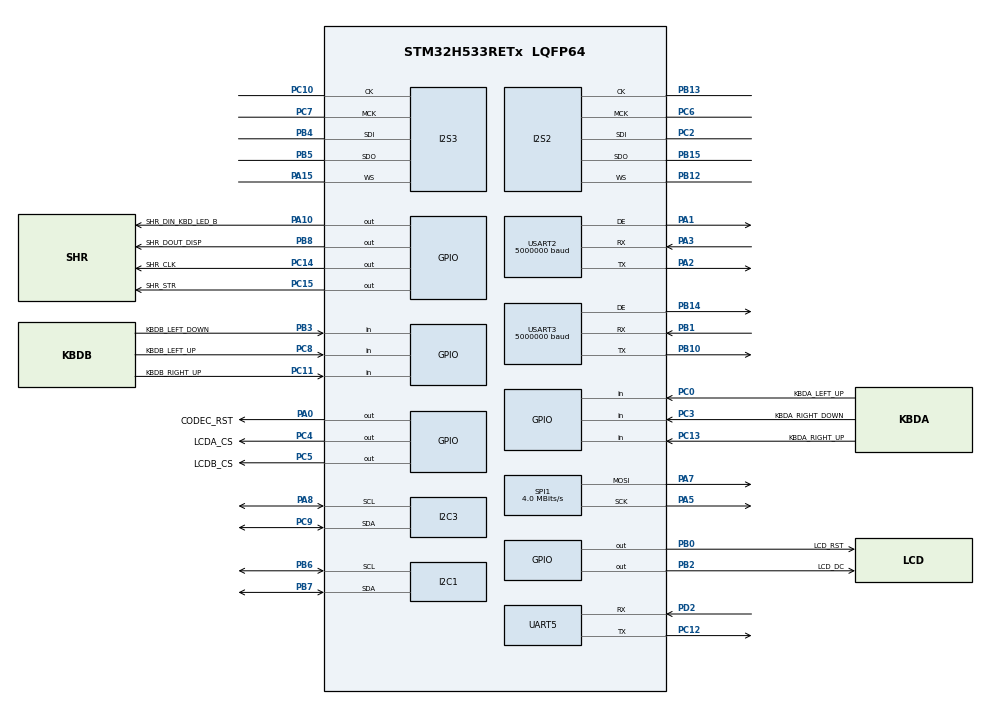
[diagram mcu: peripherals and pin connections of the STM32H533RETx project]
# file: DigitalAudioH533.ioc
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BOOTPATH.BootPathName=LEGACY
BOOTPATH.UserSelectedBootPath=LEGACY
CORTEX_M33_NS.userName=CORTEX_M33
GPDMA1.CIRCULARMODE_GPDMACH1=ENABLE
GPDMA1.CIRCULARMODE_GPDMACH3=ENABLE
GPDMA1.DESTINC_GPDMACH1=DMA_DINC_INCREMENTED
GPDMA1.DESTINC_GPDMACH3=DMA_DINC_INCREMENTED
GPDMA1.DIRECTION_GPDMACH0=DMA_MEMORY_TO_PERIPH
GPDMA1.DIRECTION_GPDMACH2=DMA_MEMORY_TO_PERIPH
GPDMA1.IPHANDLE_GPDMACH0-SIMPLEREQUEST_GPDMACH0=__NULL
GPDMA1.IPHANDLE_GPDMACH1-SIMPLEREQUEST_GPDMACH1=__NULL
GPDMA1.IPHANDLE_GPDMACH2-SIMPLEREQUEST_GPDMACH2=__NULL
GPDMA1.IPHANDLE_GPDMACH3-SIMPLEREQUEST_GPDMACH3=__NULL
GPDMA1.LINKALLOCATEDPORT_CIRCULAR_GPDMACH1=DMA_LINK_ALLOCATED_PORT1
GPDMA1.LINKALLOCATEDPORT_CIRCULAR_GPDMACH3=DMA_LINK_ALLOCATED_PORT1
GPDMA1.REQUEST_GPDMACH0=GPDMA1_REQUEST_USART3_TX
GPDMA1.REQUEST_GPDMACH1=GPDMA1_REQUEST_USART3_RX
GPDMA1.REQUEST_GPDMACH2=GPDMA1_REQUEST_USART2_TX
GPDMA1.REQUEST_GPDMACH3=GPDMA1_REQUEST_USART2_RX
GPDMA1.SRCINC_GPDMACH0=DMA_SINC_INCREMENTED
GPDMA1.SRCINC_GPDMACH2=DMA_SINC_INCREMENTED
GPDMA1.TRANSFERALLOCATEDPORTDEST_GPDMACH1=DMA_DEST_ALLOCATED_PORT1
GPDMA1.TRANSFERALLOCATEDPORTDEST_GPDMACH3=DMA_DEST_ALLOCATED_PORT1
GPDMA1.TRANSFERALLOCATEDPORTSRC_GPDMACH0=DMA_SRC_ALLOCATED_PORT1
GPDMA1.TRANSFERALLOCATEDPORTSRC_GPDMACH1=DMA_SRC_ALLOCATED_PORT0
GPDMA1.TRANSFERALLOCATEDPORTSRC_GPDMACH2=DMA_SRC_ALLOCATED_PORT1
GPDMA1.TRANSFEREVENTMODE_LL_CIRCULAR_GPDMACH1=DMA_TCEM_BLOCK_TRANSFER
GPDMA2.CIRCULARMODE_GPDMACH0=ENABLE
GPDMA2.CIRCULARMODE_GPDMACH1=ENABLE
GPDMA2.CIRCULARMODE_GPDMACH2=ENABLE
GPDMA2.CIRCULARMODE_GPDMACH3=ENABLE
GPDMA2.DESTDATAWIDTH_GPDMACH0=DMA_DEST_DATAWIDTH_WORD
GPDMA2.DESTDATAWIDTH_GPDMACH1=DMA_DEST_DATAWIDTH_WORD
GPDMA2.DESTDATAWIDTH_GPDMACH2=DMA_DEST_DATAWIDTH_WORD
GPDMA2.DESTDATAWIDTH_GPDMACH3=DMA_DEST_DATAWIDTH_WORD
GPDMA2.DESTINC_GPDMACH1=DMA_DINC_INCREMENTED
GPDMA2.DESTINC_GPDMACH3=DMA_DINC_INCREMENTED
GPDMA2.DIRECTION_GPDMACH0=DMA_MEMORY_TO_PERIPH
GPDMA2.DIRECTION_GPDMACH2=DMA_MEMORY_TO_PERIPH
GPDMA2.IPHANDLE_GPDMACH0-SIMPLEREQUEST_GPDMACH0=__NULL
GPDMA2.IPHANDLE_GPDMACH1-SIMPLEREQUEST_GPDMACH1=__NULL
GPDMA2.IPHANDLE_GPDMACH2-SIMPLEREQUEST_GPDMACH2=__NULL
GPDMA2.IPHANDLE_GPDMACH3-SIMPLEREQUEST_GPDMACH3=__NULL
GPDMA2.LINKALLOCATEDPORT_CIRCULAR_GPDMACH0=DMA_LINK_ALLOCATED_PORT1
GPDMA2.LINKALLOCATEDPORT_CIRCULAR_GPDMACH1=DMA_LINK_ALLOCATED_PORT1
GPDMA2.LINKALLOCATEDPORT_CIRCULAR_GPDMACH2=DMA_LINK_ALLOCATED_PORT1
GPDMA2.LINKALLOCATEDPORT_CIRCULAR_GPDMACH3=DMA_LINK_ALLOCATED_PORT1
GPDMA2.REQUEST_GPDMACH0=GPDMA2_REQUEST_SPI2_TX
GPDMA2.REQUEST_GPDMACH1=GPDMA2_REQUEST_SPI2_RX
GPDMA2.REQUEST_GPDMACH2=GPDMA2_REQUEST_SPI3_TX
GPDMA2.REQUEST_GPDMACH3=GPDMA2_REQUEST_SPI3_RX
GPDMA2.SRCDATAWIDTH_GPDMACH0=DMA_SRC_DATAWIDTH_WORD
GPDMA2.SRCDATAWIDTH_GPDMACH1=DMA_SRC_DATAWIDTH_WORD
GPDMA2.SRCDATAWIDTH_GPDMACH2=DMA_SRC_DATAWIDTH_WORD
GPDMA2.SRCDATAWIDTH_GPDMACH3=DMA_SRC_DATAWIDTH_WORD
GPDMA2.SRCINC_GPDMACH0=DMA_SINC_INCREMENTED
GPDMA2.SRCINC_GPDMACH2=DMA_SINC_INCREMENTED
GPDMA2.TRANSFERALLOCATEDPORTDEST_GPDMACH1=DMA_DEST_ALLOCATED_PORT1
GPDMA2.TRANSFERALLOCATEDPORTDEST_GPDMACH3=DMA_DEST_ALLOCATED_PORT1
GPDMA2.TRANSFERALLOCATEDPORTSRC_GPDMACH0=DMA_SRC_ALLOCATED_PORT1
GPDMA2.TRANSFERALLOCATEDPORTSRC_GPDMACH2=DMA_SRC_ALLOCATED_PORT1
I2C1.Timing=0x00707CBB
I2C3.Timing=0x00707CBB
I2S2.AudioFreq=AudioFreqCustomValue
I2S2.AudioFreqCustom=32000
I2S2.DataFormat=I2S_DATAFORMAT_32B
I2S2.ErrorAudioFreq=0.0 %
I2S2.Instance=SPI$Index
I2S2.RealAudioFreq=32.0 KHz
I2S3.AudioFreq=AudioFreqCustomValue
I2S3.AudioFreqCustom=32000
I2S3.DataFormat=I2S_DATAFORMAT_32B
I2S3.ErrorAudioFreq=0.0 %
I2S3.Instance=SPI$Index
I2S3.RealAudioFreq=32.0 KHz
Mcu.Family=STM32H5
Mcu.Name=STM32H533RETx
Mcu.Package=LQFP64
NVIC.PriorityGroup=NVIC_PRIORITYGROUP_4
NVIC.UART5_IRQn=true\:0\:0\:false\:false\:false\:true\:false\:true
PA0.GPIO_Label=CODEC_RST
PA0.GPIO_ModeDefaultOutputPP=GPIO_MODE_OUTPUT_OD
PA0.GPIO_PuPd=GPIO_PULLUP
PA0.PinState=GPIO_PIN_SET
PA0.Signal=GPIO_Output
PA1.GPIO_Speed=GPIO_SPEED_FREQ_HIGH
PA1.Mode=Hardware Flow Control (RS485)
PA1.Signal=USART2_DE
PA10.GPIO_Label=SHR_DIN_KBD_LED_B
PA10.PinState=GPIO_PIN_SET
PA10.Signal=GPIO_Output
PA13(JTMS/SWDIO).Mode=Serial_Wire
PA13(JTMS/SWDIO).Signal=DEBUG_JTMS-SWDIO
PA14(JTCK/SWCLK).Mode=Serial_Wire
PA14(JTCK/SWCLK).Signal=DEBUG_JTCK-SWCLK
PA15(JTDI).GPIO_Speed=GPIO_SPEED_FREQ_MEDIUM
PA15(JTDI).Mode=Full_Duplex_Master
PA15(JTDI).Signal=I2S3_WS
PA2.GPIO_Speed=GPIO_SPEED_FREQ_HIGH
PA2.Mode=Asynchronous
PA2.Signal=USART2_TX
PA3.GPIO_Speed=GPIO_SPEED_FREQ_HIGH
PA3.Mode=Asynchronous
PA3.PinAttribute=Free
PA3.Signal=USART2_RX
PA5.GPIO_Speed=GPIO_SPEED_FREQ_MEDIUM
PA5.Mode=TX_Only_Simplex_Unidirect_Master
PA5.Signal=SPI1_SCK
PA7.GPIO_Speed=GPIO_SPEED_FREQ_MEDIUM
PA7.Mode=TX_Only_Simplex_Unidirect_Master
PA7.Signal=SPI1_MOSI
PA8.Mode=I2C
PA8.Signal=I2C3_SCL
PB0.GPIO_Label=LCD_RST
PB0.Signal=GPIO_Output
PB1.GPIO_Speed=GPIO_SPEED_FREQ_HIGH
PB1.Mode=Asynchronous
PB1.PinAttribute=Free
PB1.Signal=USART3_RX
PB10.GPIO_Speed=GPIO_SPEED_FREQ_HIGH
PB10.Mode=Asynchronous
PB10.PinAttribute=Free
PB10.Signal=USART3_TX
PB12.GPIO_Speed=GPIO_SPEED_FREQ_MEDIUM
PB12.Mode=Full_Duplex_Master
PB12.PinAttribute=Free
PB12.Signal=I2S2_WS
PB13.GPIO_Speed=GPIO_SPEED_FREQ_MEDIUM
PB13.Mode=Full_Duplex_Master
PB13.PinAttribute=Free
PB13.Signal=I2S2_CK
PB14.GPIO_Speed=GPIO_SPEED_FREQ_HIGH
PB14.Mode=Hardware Flow Control (RS485)
PB14.PinAttribute=Free
PB14.Signal=USART3_DE
PB15.GPIO_Speed=GPIO_SPEED_FREQ_MEDIUM
PB15.Mode=Full_Duplex_Master
PB15.PinAttribute=Free
PB15.Signal=I2S2_SDO
PB2.GPIO_Label=LCD_DC
PB2.Signal=GPIO_Output
PB3(JTDO/TRACESWO).GPIO_Label=KBDB_LEFT_DOWN
PB3(JTDO/TRACESWO).GPIO_PuPd=GPIO_PULLUP
PB3(JTDO/TRACESWO).Signal=GPIO_Input
PB4(NJTRST).GPIO_Speed=GPIO_SPEED_FREQ_MEDIUM
PB4(NJTRST).Mode=Full_Duplex_Master
PB4(NJTRST).Signal=I2S3_SDI
PB5.GPIO_Speed=GPIO_SPEED_FREQ_MEDIUM
PB5.Mode=Full_Duplex_Master
PB5.Signal=I2S3_SDO
PB6.Mode=I2C
PB6.PinAttribute=Free
PB6.Signal=I2C1_SCL
PB7.Mode=I2C
PB7.PinAttribute=Free
PB7.Signal=I2C1_SDA
PB8.GPIO_Label=SHR_DOUT_DISP
PB8.PinAttribute=Free
PB8.Signal=GPIO_Output
PC0.GPIO_Label=KBDA_LEFT_UP
PC0.GPIO_PuPd=GPIO_PULLUP
PC0.Signal=GPIO_Input
PC10.GPIO_Speed=GPIO_SPEED_FREQ_MEDIUM
PC10.Mode=Full_Duplex_Master
PC10.Signal=I2S3_CK
PC11.GPIO_Label=KBDB_RIGHT_UP
PC11.GPIO_PuPd=GPIO_PULLUP
PC11.Signal=GPIO_Input
PC12.Mode=Asynchronous
PC12.PinAttribute=Free
PC12.Signal=UART5_TX
PC13.GPIO_Label=KBDA_RIGHT_UP
PC13.GPIO_PuPd=GPIO_PULLUP
PC13.Signal=GPIO_Input
PC14-OSC32_IN(OSC32_IN).GPIO_Label=SHR_CLK
PC14-OSC32_IN(OSC32_IN).PinAttribute=Free
PC14-OSC32_IN(OSC32_IN).Signal=GPIO_Output
PC15-OSC32_OUT(OSC32_OUT).GPIO_Label=SHR_STR
PC15-OSC32_OUT(OSC32_OUT).PinAttribute=Free
PC15-OSC32_OUT(OSC32_OUT).Signal=GPIO_Output
PC2.GPIO_Speed=GPIO_SPEED_FREQ_MEDIUM
PC2.Mode=Full_Duplex_Master
PC2.Signal=I2S2_SDI
PC3.GPIO_Label=KBDA_RIGHT_DOWN
PC3.GPIO_PuPd=GPIO_PULLUP
PC3.Signal=GPIO_Input
PC4.GPIO_Label=LCDA_CS
PC4.GPIO_Speed=GPIO_SPEED_FREQ_MEDIUM
PC4.Signal=GPIO_Output
PC5.GPIO_Label=LCDB_CS
PC5.GPIO_Speed=GPIO_SPEED_FREQ_MEDIUM
PC5.Signal=GPIO_Output
PC6.GPIO_Speed=GPIO_SPEED_FREQ_HIGH
PC6.Mode=Master_Clock_Activated
PC6.Signal=I2S2_MCK
PC7.GPIO_Speed=GPIO_SPEED_FREQ_HIGH
PC7.Mode=Master_Clock_Activated
PC7.Signal=I2S3_MCK
PC8.GPIO_Label=KBDB_LEFT_UP
PC8.GPIO_PuPd=GPIO_PULLUP
PC8.Signal=GPIO_Input
PC9.Mode=I2C
PC9.Signal=I2C3_SDA
PD2.Mode=Asynchronous
PD2.PinAttribute=Free
PD2.Signal=UART5_RX
PH0-OSC_IN(PH0).Mode=HSE-External-Oscillator
PH0-OSC_IN(PH0).Signal=RCC_OSC_IN
PH1-OSC_OUT(PH1).Mode=HSE-External-Oscillator
PH1-OSC_OUT(PH1).Signal=RCC_OSC_OUT
ProjectManager.HeapSize=0x200
ProjectManager.StackSize=0x400
ProjectManager.TargetToolchain=STM32CubeIDE
RCC.ADCFreq_Value=80000000
RCC.AHBFreq_Value=80000000
RCC.APB1Freq_Value=80000000
RCC.APB1TimFreq_Value=80000000
RCC.APB2Freq_Value=80000000
RCC.APB2TimFreq_Value=80000000
RCC.APB3Freq_Value=80000000
RCC.CKPERSourceSelection=RCC_CLKPSOURCE_HSE
RCC.CSI_VALUE=4000000
RCC.CortexFreq_Value=80000000
RCC.EPOD_VALUE=16000000
RCC.HCLKFreq_Value=80000000
RCC.HSE_VALUE=16000000
RCC.HSI48_VALUE=48000000
RCC.HSI_VALUE=64000000
RCC.I2C1CLockSelection=RCC_I2C1CLKSOURCE_PLL3R
RCC.I2C3CLockSelection=RCC_I2C3CLKSOURCE_PLL3R
RCC.LSE_VALUE=32768
RCC.LSIRC_VALUE=32000
RCC.PLL1P=4
RCC.PLL1Q=10
RCC.PLL2M=10
RCC.PLL2N=256
RCC.PLL2P=10
RCC.PLL2Q=10
RCC.PLL2Source=RCC_PLL2_SOURCE_HSE
RCC.PLL3N=8
RCC.PLL3Q=4
RCC.PLL3R=4
RCC.PLL3Source=RCC_PLL3_SOURCE_HSE
RCC.PLLN=20
RCC.PLLSourceVirtual=RCC_PLL1_SOURCE_HSE
RCC.SPI2CLockSelection=RCC_SPI2CLKSOURCE_PLL2P
RCC.SPI3CLockSelection=RCC_SPI3CLKSOURCE_PLL2P
RCC.SYSCLKFreq_VALUE=80000000
RCC.SYSCLKSource=RCC_SYSCLKSOURCE_PLLCLK
RCC.UART5CLockSelection=RCC_UART5CLKSOURCE_PLL3Q
RCC.USBFreq_Value=48000000
RCC.VCOOutputFreq_Value=320000000
SPI1.BaudRatePrescaler=SPI_BAUDRATEPRESCALER_8
SPI1.CLKPhase=SPI_PHASE_2EDGE
SPI1.CLKPolarity=SPI_POLARITY_HIGH
SPI1.CalculateBaudRate=4.0 MBits/s
SPI1.DataSize=SPI_DATASIZE_8BIT
SPI1.Direction=SPI_DIRECTION_2LINES_TXONLY
SPI1.Mode=SPI_MODE_MASTER
SPI1.VirtualType=VM_MASTER
TIM2.Prescaler=39999
TIM5.Prescaler=79
USART2.BaudRate=5000000
USART2.VirtualMode-Asynchronous=VM_ASYNC
USART2.VirtualMode-Hardware\ Flow\ Control\ (RS485)=VM_ASYNC
USART3.BaudRate=5000000
USART3.OverSampling=UART_OVERSAMPLING_16
USART3.VirtualMode-Asynchronous=VM_ASYNC
USART3.VirtualMode-Hardware\ Flow\ Control\ (RS485)=VM_ASYNC
VP_BOOTPATH_VS_BOOTPATH.Mode=BP_Activate
VP_CORTEX_M33_NS_VS_Hclk.Mode=Hclk_Mode
VP_GPDMA1_VS_GPDMACH0.Mode=SIMPLEREQUEST_GPDMACH0
VP_GPDMA1_VS_GPDMACH1.Mode=SIMPLEREQUEST_GPDMACH1
VP_GPDMA1_VS_GPDMACH2.Mode=SIMPLEREQUEST_GPDMACH2
VP_GPDMA1_VS_GPDMACH3.Mode=SIMPLEREQUEST_GPDMACH3
VP_GPDMA2_VS_GPDMACH0.Mode=SIMPLEREQUEST_GPDMACH0
VP_GPDMA2_VS_GPDMACH1.Mode=SIMPLEREQUEST_GPDMACH1
VP_GPDMA2_VS_GPDMACH2.Mode=SIMPLEREQUEST_GPDMACH2
VP_GPDMA2_VS_GPDMACH3.Mode=SIMPLEREQUEST_GPDMACH3
VP_ICACHE_VS_ICACHE.Mode=DefaultMode
VP_MEMORYMAP_VS_MEMORYMAP.Mode=CurAppReg
VP_PWR_VS_LPOM.Mode=PowerOptimisation
VP_PWR_VS_SECSignals.Mode=Security/Privilege
VP_TIM2_VS_ClockSourceINT.Mode=Internal
VP_TIM5_VS_ClockSourceINT.Mode=Internal
board=custom

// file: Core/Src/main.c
/* USER CODE BEGIN Header */
/**
********************************************************************************
* @file           : main.c
* @brief          : Main program body
********************************************************************************
*
* Copyright (c) 2026 Unicod
*
* Licensed under the Apache License, Version 2.0 (the "License");
* you may not use this file except in compliance with the License.
* You may obtain a copy of the License at
*
*     http://www.apache.org/licenses/LICENSE-2.0
*
* Unless required by applicable law or agreed to in writing, software
* distributed under the License is distributed on an "AS IS" BASIS,
* WITHOUT WARRANTIES OR CONDITIONS OF ANY KIND, either express or implied.
* See the License for the specific language governing permissions and
* limitations under the License.
*
********************************************************************************
*/
/* USER CODE END Header */
#include "main.h"

/* USER CODE BEGIN Includes */
#include <ctype.h>
#include <stdint.h>
#include <string.h>

#include "disp7seg.h"
#include "gitinfo.h"
#include "printf.h"
#include "sounds.h"
#include "tlv320aic3104_ctrl.h"
#include "u8g2.h"
#include "usart2_dma.h"
#include "usart3_dma.h"
#include "uart5_it.h"
#include "ui.h"
#include "wavetable.h"

/* USER CODE END Includes */

/* USER CODE BEGIN PTD */

#define AUDIO_TX_CHAN_CNT           2     // Audio channel count for sending on RS485 bus
#define AUDIO_BUF_SAMPLE_CNT        512   // Audio buffer size in samples (per channel)

typedef struct {
   const DMA_TypeDef* dma;       // GPDMA instance (GPDMA1 or GPDMA2)
   uint32_t    dmaChannel;       // DMA channel used for this audio DAC
   uint32_t*   dmaBuf;           // DMA buffer for audio samples (32-bit words, left justified 16-bit samples in upper half, stereo interleaved)
   uint32_t    dmaBufSizeBytes;  // Size of DMA buffer in bytes
   uint32_t    dmaBufSampleCnt;  // Number of audio samples (per channel) in DMA buffer (dmaBufSizeBytes / 4 / 2)
   uint32_t    PrevSampleIdx;    // Previous sample index processed in DMA buffer, used to detect new samples for processing
   uint8_t     AudioChSel;       // Audio channel selection by user for this DAC

   uint32_t    Phase;
   uint32_t    PhaseInc;         // phase increment
   int16_t     IncDir;           // phase increment direction for modulation: -1 or +1

   int16_t  AudioChanBuf[AUDIO_BUF_SAMPLE_CNT];   // Audio sample buffer for each channel, filled by audio ADC task and consumed by RS485 bus task. Each sample is 16-bit signed integer.
   uint16_t AudioWrPos;   // Write position in audio buffer (in samples)
   uint16_t AudioRdPos;   // Read position in audio buffer (in samples)
   uint16_t AudioDatCnt;  // Number of valid audio samples in buffer (per channel)
   uint8_t  playing;      // flag indicating if audio is currently playing (1) or buffering (0)
} AudioDac;

/* USER CODE END PTD */

/* USER CODE BEGIN PD */
#define ARRAY_COUNT(arr) (sizeof(arr) / sizeof((arr)[0]))

/* USER CODE END PD */

LL_DMA_LinkNodeTypeDef Node_GPDMA2_Channel1;
LL_DMA_LinkNodeTypeDef Node_GPDMA2_Channel0;
LL_DMA_LinkNodeTypeDef Node_GPDMA2_Channel3;
LL_DMA_LinkNodeTypeDef Node_GPDMA2_Channel2;

LL_DMA_LinkNodeTypeDef Node_GPDMA1_Channel3;
LL_DMA_LinkNodeTypeDef Node_GPDMA1_Channel1;

/* USER CODE BEGIN PV */

#define I2S2_RXDMA_BUF_SAMPLE_CNT   512
#define I2S2_TXDMA_BUF_SAMPLE_CNT   512

uint32_t I2S2RxDmaBuf[I2S2_RXDMA_BUF_SAMPLE_CNT][2] = {0};
uint32_t I2S2TxDmaBuf[I2S2_TXDMA_BUF_SAMPLE_CNT][2] = {0};

#define I2S3_RXDMA_BUF_SAMPLE_CNT   512
#define I2S3_TXDMA_BUF_SAMPLE_CNT   512

uint32_t I2S3RxDmaBuf[I2S3_RXDMA_BUF_SAMPLE_CNT][2] = {0};
uint32_t I2S3TxDmaBuf[I2S3_TXDMA_BUF_SAMPLE_CNT][2] = {0};

AudioDac AudioDac_A = {GPDMA2, LL_DMA_CHANNEL_0, (uint32_t*)I2S2TxDmaBuf, sizeof(I2S2TxDmaBuf), I2S2_TXDMA_BUF_SAMPLE_CNT, 0, 3, 0, (4UL << 14), 1};
AudioDac AudioDac_B = {GPDMA2, LL_DMA_CHANNEL_2, (uint32_t*)I2S3TxDmaBuf, sizeof(I2S3TxDmaBuf), I2S3_TXDMA_BUF_SAMPLE_CNT, 0, 4, 0, (4UL << 14), 1};

uint8_t Vol = 0;

// Display instances for OLED LCD A and LCD B
static u8g2_t LcdA;
static u8g2_t LcdB;

/* USER CODE END PV */

void SystemClock_Config(void);
void PeriphCommonClock_Config(void);
static void MX_GPIO_Init(void);
static void MX_GPDMA1_Init(void);
static void MX_GPDMA2_Init(void);
static void MX_ICACHE_Init(void);
static void MX_TIM5_Init(void);
static void MX_TIM2_Init(void);
static void MX_USART3_UART_Init(void);
static void MX_UART5_Init(void);
static void MX_USART2_UART_Init(void);
static void MX_I2S2_Init(void);
static void MX_I2C1_Init(void);
static void MX_I2S3_Init(void);
static void MX_I2C3_Init(void);
static void MX_SPI1_Init(void);

/* USER CODE BEGIN 0 */
static inline void LD2_On()     { LL_GPIO_SetOutputPin(  SHR_DIN_KBD_LED_B_GPIO_Port, SHR_DIN_KBD_LED_B_Pin); }
static inline void LD2_Off()    { LL_GPIO_ResetOutputPin(SHR_DIN_KBD_LED_B_GPIO_Port, SHR_DIN_KBD_LED_B_Pin); }
static inline void LD2_Toggle() { LL_GPIO_TogglePin(     SHR_DIN_KBD_LED_B_GPIO_Port, SHR_DIN_KBD_LED_B_Pin); }

static inline void LCDA_CS_Deselect()   { LL_GPIO_SetOutputPin( LCDA_CS_GPIO_Port, LCDA_CS_Pin);   }
static inline void LCDA_CS_Select()     { LL_GPIO_ResetOutputPin( LCDA_CS_GPIO_Port, LCDA_CS_Pin); }

static inline void LCDB_CS_Deselect()   { LL_GPIO_SetOutputPin( LCDB_CS_GPIO_Port, LCDB_CS_Pin);   }
static inline void LCDB_CS_Select()     { LL_GPIO_ResetOutputPin( LCDB_CS_GPIO_Port, LCDB_CS_Pin); }

static inline void LCD_DC_High()        { LL_GPIO_SetOutputPin( LCD_DC_GPIO_Port, LCD_DC_Pin);   }
static inline void LCD_DC_Low()         { LL_GPIO_ResetOutputPin( LCD_DC_GPIO_Port, LCD_DC_Pin); }

static inline void LCD_RST_High()       { LL_GPIO_SetOutputPin( LCD_RST_GPIO_Port, LCD_RST_Pin);   }
static inline void LCD_RST_Low()        { LL_GPIO_ResetOutputPin( LCD_RST_GPIO_Port, LCD_RST_Pin); }

/***************************************************************************//**
 * @brief Check if specified time interval has elapsed
 * @param tref Pointer to time reference variable [ms]
 * @param tcycle Time interval in milliseconds
 *//****************************************************************************/
static inline uint32_t TickChk(uint32_t *tref, int_fast16_t tcycle) {
   uint32_t t = LL_TIM_GetCounter(TIM2) / 2;    // 2kHz/2=1kHz
   int32_t tdif = t - *tref;
   if (tdif >= tcycle) {
      *tref += tcycle;
      return 1;
   }
   return 0;
}

/***************************************************************************//**
* @brief Character send interface for printf function
*//****************************************************************************/
void uart_putc (void* p, char c) {
   Uart5_PutByte(c);
}

/***************************************************************************//**
* @brief Audio statistics
*//****************************************************************************/
void AudioStat(int16_t left, int16_t right) {
   static int32_t SumL = 0;
   static int32_t SumR = 0;
   static int16_t MinL = 0;
   static int16_t MaxL = 0;
   static int16_t MinR = 0;
   static int16_t MaxR = 0;
   SumL += left;
   SumR += right;
   if (left < MinL) MinL = left;
   if (left > MaxL) MaxL = left;
   if (right < MinR) MinR = right;
   if (right > MaxR) MaxR = right;
   static uint32_t PrintDelay = 0;
   if (++PrintDelay == 32000) {   // print every 32000 samples (approx every 1s at 32kHz sample rate)
      PrintDelay = 0;
      printf("A:%d,%d L(%d %d) R(%d %d)\n", SumL/32000, SumR/32000, MinL, MaxL, MinR, MaxR);
      SumL = 0;
      SumR = 0;
      MinL = INT16_MAX;
      MaxL = INT16_MIN;
      MinR = INT16_MAX;
      MaxR = INT16_MIN;
   }
}

/***************************************************************************//**
* @brief Process received data from USART2 (DMA rx callback)
*//****************************************************************************/
void ProcessUsart2RxData(const uint8_t* data, uint16_t len) {
}

/***************************************************************************//**
* @brief Process received data from USART3 (DMA rx callback)
*
* Decode audio packets received on USART3 (RS485 bus) and store audio samples
* in buffer for playback.
*
* Packet format [bytes]:
* [Header1]
* [Header2]
* [Channel]
* [Sample1_L]
* [Sample1_H]
* [Sample2_L]
* [Sample2_H]
* ...
* [SampleN_L]
* [SampleN_H]
*
*//****************************************************************************/
void ProcessUsart3RxData(const uint8_t* data, uint16_t len) {
#if 0
   static uint32_t ByteCnt = 0;
   static uint32_t SampleCnt = 0;
   ByteCnt += len;
   const uint16_t PacketSize = 3 + 128 * 2;  // Packet header (3 bytes) + 128 samples * 2 bytes per sample
   if (ByteCnt >= PacketSize) {
      ByteCnt -= PacketSize;
      SampleCnt += 128;
      if (SampleCnt >= 32000) {
         SampleCnt -= 32000;
         printf("AudioRx %u ms\n", usTimerGetAbs() / 1000); // Print timestamp every 32k samples (every 1 second at 32kHz sample rate)
      }
   }
#endif

   #define  DAT_IDX_START1       (-3)
   #define  DAT_IDX_START2       (DAT_IDX_START1 + 1)
   #define  DAT_IDX_CHANNEL      (DAT_IDX_START2 + 1)
   #define  AUDIO_PACKET_SIZE    256
   #define  AUDIO_CHANNELS       8

   #define  CIN_START1     111
   #define  CIN_START2     222

   static int16_t DatCnt = DAT_IDX_START1;
   static uint8_t ChanMatchA = 0;
   static uint8_t ChanMatchB = 0;
   static uint8_t LSB = 0;

   uint8_t ovfdiag = 1;
   for (size_t i=0; i<len; i++) {
      uint8_t d = data[i];
      switch (DatCnt) {
         case DAT_IDX_START1: {
            if (d == CIN_START1) DatCnt++;
         }break;
         case DAT_IDX_START2: {
            if (d == CIN_START2) DatCnt++;
            else DatCnt = DAT_IDX_START1;       // reset
         }break;
         case DAT_IDX_CHANNEL: {
            if (d < AUDIO_CHANNELS) {           // channel number range OK
               ChanMatchA = (d == AudioDac_A.AudioChSel) ? 1 : 0; // check channel number
               ChanMatchB = (d == AudioDac_B.AudioChSel) ? 1 : 0;
               DatCnt++;
               //printf("Ch%u\n", AudioChan);
            }else {                             // channel number out of range (invalid packet)
               DatCnt = DAT_IDX_START1;         // reset
            }
         }break;
         default: {
            if ((DatCnt & 1) == 0) {   // even index: LSByte
               LSB = d;                // store LSByte
            }else {                    // odd index: MSByte
               int16_t sample = ((uint16_t)d << 8) | LSB;   // combine MSByte and LSByte to form signed 16-bit audio sample
               //AudioStat(sample, 0);

               // Store received audio samples from RS485 to audio buffer
               if (ChanMatchA) {
                  AudioDac* d = &AudioDac_A;
                  if (d->AudioDatCnt < AUDIO_BUF_SAMPLE_CNT-1) {
                     d->AudioDatCnt++;
                     d->AudioWrPos++; // increment position
                     if (d->AudioWrPos >= AUDIO_BUF_SAMPLE_CNT) d->AudioWrPos = 0;  // wrap around if end of buffer reached
                     d->AudioChanBuf[d->AudioWrPos] = sample;     // store audio sample
                  }else {
                     if (ovfdiag) {
                        ovfdiag = 0;
                        printf("f");   // overflow
                     }
                  }
               }
               if (ChanMatchB) {
                  AudioDac* d = &AudioDac_B;
                  if (d->AudioDatCnt < AUDIO_BUF_SAMPLE_CNT-1) {
                     d->AudioDatCnt++;
                     d->AudioWrPos++; // increment position
                     if (d->AudioWrPos >= AUDIO_BUF_SAMPLE_CNT) d->AudioWrPos = 0;  // wrap around if end of buffer reached
                     d->AudioChanBuf[d->AudioWrPos] = sample;     // store audio sample
                  }else {
                     if (ovfdiag) {
                        ovfdiag = 0;
                        printf("F");   // overflow
                     }
                  }
               }
            }
            if (++DatCnt == AUDIO_PACKET_SIZE) DatCnt = DAT_IDX_START1; // done
         }break;
      }
   }

}

/***************************************************************************//**
* @brief  List specified registers of TLV320AIC3204 codec for debugging
*//****************************************************************************/
void TLV320_AIC3204_DumpRegs(void) {
   printf("TLV320_AIC3204: Dumping registers...\n");

   CODEC_SELECT    codec = CODEC_A;
   TLV_PAGE_SELECT page = TLV_PAGE_0;
   uint8_t         reg_list[] = { 0,2,3,4,5,6,7,8,9,10,11,47,51,43,37,44,64,65,38 };

   for (size_t i = 0; i < ARRAY_COUNT(reg_list); i++) {
      uint8_t reg = reg_list[i];
      int16_t val = TlvReadReg(codec, page, reg);
      printf("Reg %2u: 0x%02X (%d) \n", reg, val, val);
   }

   printf("TLV320_AIC3204: Dump done\n");
}

/***************************************************************************//**
* @brief   TLV320AIC3204 codec init with basic config for stereo playing (DAC)
*//****************************************************************************/
void TLV320_AIC3204_Init() {
   for (uint8_t codec = CODEC_A; codec <= CODEC_B; codec++) {
      TlvWriteReg(codec, TLV_PAGE_0,   3, 0x10);
      TlvWriteReg(codec, TLV_PAGE_0,   7, 0x0A);
      TlvWriteReg(codec, TLV_PAGE_0,   9, 0x10);
      TlvWriteReg(codec, TLV_PAGE_0,  47, 0x80);
      TlvWriteReg(codec, TLV_PAGE_0,  51, 0x09);
      TlvWriteReg(codec, TLV_PAGE_0,  43, 0x00);
      TlvWriteReg(codec, TLV_PAGE_0,  37, 0xD0);
      TlvWriteReg(codec, TLV_PAGE_0,  44, 0x00);
      TlvWriteReg(codec, TLV_PAGE_0,  64, 0x80);
      TlvWriteReg(codec, TLV_PAGE_0,  65, 0x09);
      TlvWriteReg(codec, TLV_PAGE_0,  38, 0x0C);
      TlvWriteReg(codec, TLV_PAGE_0, 101, 0x01);
      TlvWriteReg(codec, TLV_PAGE_0, 102, 0x02);

      TlvWriteReg(codec, TLV_PAGE_0,  15, 0x40);
      TlvWriteReg(codec, TLV_PAGE_0,  16, 0x40);
      TlvWriteReg(codec, TLV_PAGE_0,  17, 0xFF);
      TlvWriteReg(codec, TLV_PAGE_0,  18, 0xF0);
      TlvWriteReg(codec, TLV_PAGE_0,  19, 0x0D);
      TlvWriteReg(codec, TLV_PAGE_0,  21, 0x80);
      TlvWriteReg(codec, TLV_PAGE_0,  22, 0xFD);
      TlvWriteReg(codec, TLV_PAGE_0,  24, 0xF8);
      TlvWriteReg(codec, TLV_PAGE_0,  25, 0x80);
      TlvWriteReg(codec, TLV_PAGE_0,  40, 0xC1);
      TlvWriteReg(codec, TLV_PAGE_0,  41, 0x02);
      TlvWriteReg(codec, TLV_PAGE_0,  42, 0x88);
      TlvWriteReg(codec, TLV_PAGE_0,  46, 0x00);
      TlvWriteReg(codec, TLV_PAGE_0,  49, 0x00);
      TlvWriteReg(codec, TLV_PAGE_0,  50, 0x00);
      TlvWriteReg(codec, TLV_PAGE_0,  53, 0x00);
      TlvWriteReg(codec, TLV_PAGE_0,  54, 0x00);
      TlvWriteReg(codec, TLV_PAGE_0,  56, 0x00);
      TlvWriteReg(codec, TLV_PAGE_0,  57, 0x00);
      TlvWriteReg(codec, TLV_PAGE_0,  58, 0x01);
      TlvWriteReg(codec, TLV_PAGE_0,  60, 0x00);
      TlvWriteReg(codec, TLV_PAGE_0,  61, 0x00);
      TlvWriteReg(codec, TLV_PAGE_0,  63, 0x00);
      TlvWriteReg(codec, TLV_PAGE_0,  67, 0x00);
      TlvWriteReg(codec, TLV_PAGE_0,  68, 0x00);
      TlvWriteReg(codec, TLV_PAGE_0,  70, 0x00);
      TlvWriteReg(codec, TLV_PAGE_0,  71, 0x00);
      TlvWriteReg(codec, TLV_PAGE_0,  72, 0x01);
   }
}

void Fill_I2S_Buffer(AudioDac* dac, uint32_t start_sample, uint32_t sample_count) {
   uint_fast8_t doubling = 0;
   uint_fast8_t dropping = 0;

   for (uint32_t i = 0; i < sample_count; i++) {
      int16_t pcmsample = 0;

      switch (dac->AudioChSel) {
         case 9: {
            uint32_t frac = dac->Phase & 0x3FFF;        // fractional part for interpolation (14 bits)
            uint16_t idx  = dac->Phase >> 14;           // integer part: array index
            uint16_t idx2 = (idx + 1) % ARRAY_COUNT(Wave_Sin); // next index for linear interpolation
            int32_t pcm1 = Wave_Sin[idx];          // sine waveform
            int32_t pcm2 = Wave_Sin[idx2];         // next sample for interpolation
            pcmsample = pcm1 + ((pcm2 - pcm1) * frac >> 14); // linear interpolation
            pcmsample = pcmsample / 2;             // reduce amplitude
            dac->Phase = (dac->Phase + dac->PhaseInc) % (ARRAY_COUNT(Wave_Sin) << 14); // phase accumulator with wrap-around
            if (dac->AudioChSel == 5) dac->PhaseInc += dac->IncDir;  // Chsel: 6=fixed freq, 5=sweep up and down
            if (dac->PhaseInc < ( 4UL << 14)) dac->IncDir =  1; // minimum frequency reached, change direction to up
            if (dac->PhaseInc > (16UL << 14)) dac->IncDir = -1; // maximum frequency reached, change direction to down
         }break;
         case 7: {
            uint32_t frac = dac->Phase & 0x3FFF;        // fractional part for interpolation (14 bits)
            uint16_t idx  = dac->Phase >> 14;           // integer part: array index
            uint16_t idx2 = (idx + 1) % ARRAY_COUNT(Wave_Organ); // next index for linear interpolation
            int32_t pcm1 = Wave_Organ[idx];          // sine waveform
            int32_t pcm2 = Wave_Organ[idx2];         // next sample for interpolation
            pcmsample = pcm1 + ((pcm2 - pcm1) * frac >> 14); // linear interpolation
            pcmsample = pcmsample / 2;             // reduce amplitude
            dac->Phase = (dac->Phase + dac->PhaseInc) % (ARRAY_COUNT(Wave_Organ) << 14); // phase accumulator with wrap-around
            if (dac->AudioChSel == 7) dac->PhaseInc += dac->IncDir;  // Chsel: 3=fixed freq, 4=sweep up and down
            if (dac->PhaseInc < ( 4UL << 14)) dac->IncDir =  1; // minimum frequency reached, change direction to up
            if (dac->PhaseInc > (16UL << 14)) dac->IncDir = -1; // maximum frequency reached, change direction to down
         }break;

         case 6:
         case 5:
         case 4:
         case 3:
         case 2:
         case 1:
         case 0: {
            if (dac->AudioDatCnt < (AUDIO_BUF_SAMPLE_CNT * 1 / 8)) {    // too few samples in input buffer
               if (doubling == 0) doubling = 10;
            }
            if (dac->playing) {
               if (dac->AudioDatCnt == 0) {    // no samples to play
                  pcmsample = 0;          // mute output
                  dac->playing = 0;       // stop playing until buffer is refilled
                  printf("x");
               } else {
                  int16_t d = dac->AudioChanBuf[dac->AudioRdPos];  // read audio sample
                  pcmsample = d;                         // normal playback
                  dac->AudioDatCnt--;
                  dac->AudioRdPos++;
                  if (dac->AudioRdPos >= AUDIO_BUF_SAMPLE_CNT) dac->AudioRdPos = 0;
               }
            } else {    // Buffering (wait..)
               pcmsample = 0;
               if (dac->AudioDatCnt > (AUDIO_BUF_SAMPLE_CNT / 2)) {
                  dac->playing = 1;
                  printf("w");
               }
            }
            if (dac->AudioDatCnt > (AUDIO_BUF_SAMPLE_CNT * 7 / 8)) { // too many samples in input buffer
               if (dropping == 0) dropping = 10;
            }
         }break;
      }
      int32_t frame = pcmsample << 16; // convert to 32-bit sample with 16-bit left justified
      uint32_t pos = (start_sample + i) * 2;  // Stereo: L,R
      dac->dmaBuf[pos + 0] = frame/4;   // Left
      dac->dmaBuf[pos + 1] = frame/4;   // Right

      if (doubling == 10) {
         if (i<sample_count-1) {
            int32_t frame = pcmsample << 16; // convert to 32-bit sample with 16-bit left justified
            uint32_t pos = (start_sample + i) * 2;  // Stereo: L,R
            dac->dmaBuf[pos + 0] = frame/4;   // Left (duplicate sample)
            dac->dmaBuf[pos + 1] = frame/4;   // Right
            i++;
            if (dac->playing) printf("+");
         }
      }
      if (doubling) doubling--;

      if (dropping == 5) {
         dac->AudioDatCnt--;
         dac->AudioRdPos++;  // drop sample (no output for this sample)
         if (dac->AudioRdPos >= AUDIO_BUF_SAMPLE_CNT) dac->AudioRdPos = 0;
         if (dac->playing) printf("-");
      }
      if (dropping) dropping--;

   }
}

void AudioDAC_Task(AudioDac* dac) {
   uint32_t dma_ptr = dac->dmaBufSizeBytes - LL_DMA_GetBlkDataLength(dac->dma, dac->dmaChannel);
   uint32_t sample_idx = dma_ptr / 8; // Word = 4 bytes * 2 channels = 8 bytes per sample

   if (sample_idx != dac->PrevSampleIdx) {
      uint32_t free_samples;
      if (sample_idx > dac->PrevSampleIdx) {
         free_samples = sample_idx - dac->PrevSampleIdx;         // normal case: DMA is in between old and new index
         Fill_I2S_Buffer(dac, dac->PrevSampleIdx, free_samples);
      } else {
         free_samples = dac->dmaBufSampleCnt - dac->PrevSampleIdx;   // Wrap-around
         Fill_I2S_Buffer(dac, dac->PrevSampleIdx, free_samples);     // first the rest until end of buffer
         if (sample_idx > 0) {
            Fill_I2S_Buffer(dac, 0, sample_idx);
         }
      }

      dac->PrevSampleIdx = sample_idx;
   }
   //printf("dma_ptr:%u dma_word_index:%u sample_index:%u\n", dma_ptr, dma_word_index, sample_index);
}

void Proc_I2S_Buffer(uint32_t *buf, uint32_t start_sample, uint32_t sample_count) {
   enum { BUFCNT = 7 };
   static uint8_t Buf[BUFCNT][512];
   // Create audio packets from received I2S samples and send on USART2 (RS485 bus)
   for (uint32_t i = 0; i < sample_count; i++) {
      uint32_t pos = (start_sample + i) * 2;  // Stereo: L,R
      int16_t left  = buf[pos + 0] >> 16;   // convert back to 16-bit sample from 32-bit left justified
      int16_t right = buf[pos + 1] >> 16;   // convert back to 16-bit sample from 32-bit left justified
      {
         static uint16_t ByteTxIdx = 0;   // byte index for filling audio packet buffer
         static uint16_t SampleTxIdx = 0; // index for counting audio samples in current packet
         static uint32_t PcmPos = 0;      // position in PCM sample stream [samples]
         static uint32_t Phase = 0;       // phase accumulator for sine wave generation
         static const uint32_t PhaseInc = (4UL << 14) + 2345;  // phase increment for sine wave generation (controls frequency)
         if (SampleTxIdx == 0) {          // start of new packet, fill header
            ByteTxIdx = 0;
            for (int b=0; b<BUFCNT; b++) Buf[b][ByteTxIdx] = CIN_START1; // Packet header byte 1
            ByteTxIdx++;
            for (int b=0; b<BUFCNT; b++) Buf[b][ByteTxIdx] = CIN_START2; // Packet header byte 2
            ByteTxIdx++;
            for (int b=0; b<BUFCNT; b++) Buf[b][ByteTxIdx] = b;          // channel number
            ByteTxIdx++;
         }
         enum { AUDIO_PACKET_HDR_SIZE   = 3   };   // header size in bytes
         enum { AUDIO_PACKET_SAMPLE_CNT = 128 };   // number of audio samples in one packet
         if (SampleTxIdx < AUDIO_PACKET_SAMPLE_CNT) {
            PcmPos++;   // increment position in PCM sample stream
            if (PcmPos > (PCM_DolmetscheranlageLen + 2*32000)
            &&  PcmPos > (PCM_InterpreterSystemLen + 2*32000)
            &&  PcmPos > (PCM_TolmacsrendszerLen   + 2*32000)
            ) {
               PcmPos = 0;
            }
            int16_t s_de = PCM_Dolmetscheranlage[PcmPos];
            int16_t s_en = PCM_InterpreterSystem[PcmPos];
            int16_t s_hu = PCM_Tolmacsrendszer[PcmPos];
            if (PcmPos >= PCM_DolmetscheranlageLen) s_de = 0;
            if (PcmPos >= PCM_InterpreterSystemLen) s_en = 0;
            if (PcmPos >= PCM_TolmacsrendszerLen)   s_hu = 0;

            uint32_t frac = Phase & 0x3FFF;        // fractional part for interpolation (14 bits)
            uint16_t idx  = Phase >> 14;           // integer part: array index
            uint16_t idx2 = (idx + 1) % ARRAY_COUNT(Wave_Sin); // next index for linear interpolation
            int32_t pcm1 = Wave_Sin[idx];          // sine waveform
            int32_t pcm2 = Wave_Sin[idx2];         // next sample for interpolation
            int16_t s_sin = pcm1 + ((pcm2 - pcm1) * frac >> 14); // linear interpolation
            s_sin = s_sin / 2;             // reduce amplitude
            Phase = (Phase + PhaseInc) % (ARRAY_COUNT(Wave_Sin) << 14); // phase accumulator with wrap-around

            // Low byte of 16 bit audio sample
            Buf[0][ByteTxIdx] = left & 0xFF;   // store low byte of audio sample in packet buffer
            Buf[1][ByteTxIdx] = right & 0xFF;
            Buf[2][ByteTxIdx] = s_de & 0xFF;
            Buf[3][ByteTxIdx] = s_en & 0xFF;
            Buf[4][ByteTxIdx] = s_hu & 0xFF;
            Buf[5][ByteTxIdx] = 0;
            Buf[6][ByteTxIdx] = s_sin & 0xFF;
            ByteTxIdx++;

            // High byte of 16 bit audio sample
            Buf[0][ByteTxIdx] = left >> 8;     // store high byte of audio sample in packet buffer
            Buf[1][ByteTxIdx] = right >> 8;
            Buf[2][ByteTxIdx] = s_de >> 8;
            Buf[3][ByteTxIdx] = s_en >> 8;
            Buf[4][ByteTxIdx] = s_hu >> 8;
            Buf[5][ByteTxIdx] = 0;
            Buf[6][ByteTxIdx] = s_sin >> 8;
            ByteTxIdx++;
            SampleTxIdx++;
         }
         if (SampleTxIdx == AUDIO_PACKET_SAMPLE_CNT) {         // packet is full, send it
            Usart2_TxBufWrite(Buf[0], ByteTxIdx, 0);   // write packet to USART2 DMA buffer
            Usart2_TxBufWrite(Buf[1], ByteTxIdx, 0);   // write packet to USART2 DMA buffer
            Usart2_TxBufWrite(Buf[2], ByteTxIdx, 0);   // write packet to USART2 DMA buffer
            Usart2_TxBufWrite(Buf[3], ByteTxIdx, 0);   // write packet to USART2 DMA buffer
            Usart2_TxBufWrite(Buf[4], ByteTxIdx, 0);   // write packet to USART2 DMA buffer
            Usart2_TxBufWrite(Buf[5], ByteTxIdx, 0);   // write packet to USART2 DMA buffer
            Usart2_TxBufWrite(Buf[6], ByteTxIdx, 1);   // write packet to USART2 DMA buffer and flush (start transfer)
            ByteTxIdx = 0;    // reset byte index for next packet
            SampleTxIdx = 0;  // reset sample index for next packet
         }
      }
      AudioStat(left, right);
   }
}

void AudioADC_Task(void) {
   static uint32_t old_sample_index = 0;
   // DMA pointer --> Word-Index
   uint32_t dma_ptr = sizeof(I2S2RxDmaBuf) - LL_DMA_GetBlkDataLength(GPDMA2, LL_DMA_CHANNEL_1);
   uint32_t sample_index = dma_ptr / 8; // Word = 4 bytes * 2 channels = 8 bytes per sample

   if (sample_index != old_sample_index) {
      uint32_t free_samples;
      if (sample_index > old_sample_index) {
         free_samples = sample_index - old_sample_index;         // normal case: DMA is in between old and new index
         Proc_I2S_Buffer(I2S2RxDmaBuf[0], old_sample_index, free_samples);
      } else {
         free_samples = I2S2_RXDMA_BUF_SAMPLE_CNT - old_sample_index;         // Wrap-around
         Proc_I2S_Buffer(I2S2RxDmaBuf[0], old_sample_index, free_samples); // first the rest until end of buffer
         if (sample_index > 0) {
            Proc_I2S_Buffer(I2S2RxDmaBuf[0], 0, sample_index);
         }
      }

      old_sample_index = sample_index;
   }
   //printf("dma_ptr:%u dma_word_index:%u sample_index:%u\n", dma_ptr, dma_word_index, sample_index);
}

/***************************************************************************//**
* @brief  Handle keyboard input and update state
*//****************************************************************************/
static inline void Kbd_Task(void) {
   static uint32_t KbdPrev = 0;
   uint32_t k = Kbd_ReadState();
   uint32_t pressed =   k & ~KbdPrev;  // newly pressed keys
   uint32_t released = ~k &  KbdPrev;  // newly released keys
   for (uint16_t i=0; pressed | released; i++) {
      if (pressed & 1) {
         UI_EventProcKbd(i);                    // key pressed
      }
      if (released & 1) {
         UI_EventProcKbd(i + 256);              // key released
      }
      pressed >>= 1;
      released >>= 1;
   }
   KbdPrev = k;
}

void AudioSetChannelA(uint8_t chan) { AudioDac_A.AudioChSel = chan; }
void AudioSetChannelB(uint8_t chan) { AudioDac_B.AudioChSel = chan; }

/***************************************************************************//**
* @brief  GPIO and delay callback for u8g2 library (LCD-A control)
*//****************************************************************************/
uint8_t u8x8_stm32_gpio_and_delay_LcdA(U8X8_UNUSED u8x8_t *u8x8, U8X8_UNUSED uint8_t msg, U8X8_UNUSED uint8_t arg_int, U8X8_UNUSED void *arg_ptr) {
   switch (msg) {
   case U8X8_MSG_GPIO_AND_DELAY_INIT:
      LL_mDelay(1);
      break;
   case U8X8_MSG_DELAY_MILLI:
      LL_mDelay(arg_int);
      break;
   case U8X8_MSG_GPIO_CS:
      if (arg_int) LCDA_CS_Deselect();
      else         LCDA_CS_Select();
      break;
   case U8X8_MSG_GPIO_DC:
      if (arg_int) LCD_DC_High();
      else         LCD_DC_Low();
      break;
   case U8X8_MSG_GPIO_RESET:
      if (arg_int) LCD_RST_High();
      else         LCD_RST_Low();
      break;
   }
   return 1;
}

/***************************************************************************//**
* @brief  GPIO and delay callback for u8g2 library (LCD-B control)
*//****************************************************************************/
uint8_t u8x8_stm32_gpio_and_delay_LcdB(U8X8_UNUSED u8x8_t *u8x8, U8X8_UNUSED uint8_t msg, U8X8_UNUSED uint8_t arg_int, U8X8_UNUSED void *arg_ptr) {
   switch (msg) {
   case U8X8_MSG_GPIO_AND_DELAY_INIT:
      LL_mDelay(1);
      break;
   case U8X8_MSG_DELAY_MILLI:
      LL_mDelay(arg_int);
      break;
   case U8X8_MSG_GPIO_CS:
      if (arg_int) LCDB_CS_Deselect();
      else         LCDB_CS_Select();
      break;
   case U8X8_MSG_GPIO_DC:
      if (arg_int) LCD_DC_High();
      else         LCD_DC_Low();
      break;
   case U8X8_MSG_GPIO_RESET:
      // Shared reset pin for both LCDs, handled in LcdA callback
      // Initialization order: first LcdA, then LcdB!
      // Resetting in LcdA callback will reset both LCDs
      break;
   }
   return 1;
}

/***************************************************************************//**
* @brief  Byte-level communication callback for u8g2 library (4-wire hardware SPI)
*//****************************************************************************/
uint8_t u8x8_byte_4wire_hw_spi(u8x8_t *u8x8, uint8_t msg, uint8_t arg_int, void *arg_ptr) {
   switch (msg) {
   case U8X8_MSG_BYTE_SEND:
      uint8_t* dat = (uint8_t*)arg_ptr;
      for (uint16_t i = 0; i < arg_int; i++) {
         while (!LL_SPI_IsActiveFlag_TXP(SPI1)); // wait until transmit FIFO has space
         LL_SPI_TransmitData8(SPI1, dat[i]);
      }
      while (!LL_SPI_IsActiveFlag_TXC(SPI1)); // Ensure the last byte has been physically transmitted (wait for TXC)
      break;
   case U8X8_MSG_BYTE_INIT:
      u8x8_gpio_SetCS(u8x8, u8x8->display_info->chip_disable_level);
      break;
   case U8X8_MSG_BYTE_SET_DC:
      u8x8_gpio_SetDC(u8x8, arg_int);
      break;
   case U8X8_MSG_BYTE_START_TRANSFER:
      LL_SPI_Enable(SPI1);
      LL_SPI_StartMasterTransfer(SPI1);
      u8x8_gpio_SetCS(u8x8, u8x8->display_info->chip_enable_level);
      break;
   case U8X8_MSG_BYTE_END_TRANSFER:
      u8x8_gpio_SetCS(u8x8, u8x8->display_info->chip_disable_level);
      LL_SPI_ClearFlag_TXTF(SPI1);
      LL_SPI_Disable(SPI1);
      break;
   default:
      return 0;
   }
   return 1;
}

/* USER CODE END 0 */

int main(void)
{

  /* MCU Configuration--------------------------------------------------------*/

  /* Reset of all peripherals, Initializes the Flash interface and the Systick. */

  /* System interrupt init*/
  NVIC_SetPriorityGrouping(NVIC_PRIORITYGROUP_4);

  /* SysTick_IRQn interrupt configuration */
  NVIC_SetPriority(SysTick_IRQn, NVIC_EncodePriority(NVIC_GetPriorityGrouping(),15, 0));

  /* Configure the system clock */
  SystemClock_Config();

  /* Configure the peripherals common clocks */
  PeriphCommonClock_Config();

  /* USER CODE BEGIN SysInit */

   for (uint32_t i = 0; i < I2S2_TXDMA_BUF_SAMPLE_CNT; i++) {
      int32_t a = INT32_MAX / 2 * sin(2 * 3.14159265358979323846 * i / I2S2_TXDMA_BUF_SAMPLE_CNT); // sine wave
      int32_t b = INT32_MAX / 2 * sin(4 * 3.14159265358979323846 * i / I2S2_TXDMA_BUF_SAMPLE_CNT); // sine wave at 2x frequency
      I2S2TxDmaBuf[i][0] = a; // left channel sample
      I2S2TxDmaBuf[i][1] = b; // right channel sample

      // I2S3 (Codec-B)
      I2S3TxDmaBuf[i][0] = a; // left channel sample
      I2S3TxDmaBuf[i][1] = b; // right channel sample
   }

  /* USER CODE END SysInit */

  /* Initialize all configured peripherals */
  MX_GPIO_Init();
  MX_GPDMA1_Init();
  MX_GPDMA2_Init();
  MX_ICACHE_Init();
  MX_TIM5_Init();
  MX_TIM2_Init();
  MX_USART3_UART_Init();
  MX_UART5_Init();
  MX_USART2_UART_Init();
  MX_I2S2_Init();
  MX_I2C1_Init();
  MX_I2S3_Init();
  MX_I2C3_Init();
  MX_SPI1_Init();
  /* USER CODE BEGIN 2 */

  CODEC_RST_LO();    // Reset the audio codec via HW reset pin
  __NOP();
  __NOP();
  CODEC_RST_HI();

  init_printf(NULL, &uart_putc);

  LL_TIM_GenerateEvent_UPDATE(TIM2);
  LL_TIM_EnableCounter(TIM2);
  LL_TIM_GenerateEvent_UPDATE(TIM5);
  LL_TIM_EnableCounter(TIM5);

  LL_Init1msTick(SystemCoreClock);

  DispPutDigit(0, ' ', 0);
  DispPutDigit(1, ' ', 0);
  DispPutDigit(2, ' ', 0);
  DispPutDigit(3, ' ', 0);
  ShiftReg_Update();

  Usart2_DMA_Init(ProcessUsart2RxData);
  Usart3_DMA_Init(ProcessUsart3RxData);
  Uart5_Init();

  TLV320_AIC3204_Init();

   u8g2_Setup_sh1106_128x64_noname_f(&LcdA, U8G2_R0, u8x8_byte_4wire_hw_spi, u8x8_stm32_gpio_and_delay_LcdA);
   u8g2_Setup_sh1106_128x64_noname_f(&LcdB, U8G2_R0, u8x8_byte_4wire_hw_spi, u8x8_stm32_gpio_and_delay_LcdB);
   u8g2_InitDisplay(&LcdA);
   u8g2_InitDisplay(&LcdB);
   u8g2_SetPowerSave(&LcdA, 0);
   u8g2_SetPowerSave(&LcdB, 0);

   char s[64];
   u8g2_ClearBuffer(&LcdA);
   u8g2_ClearBuffer(&LcdB);
   u8g2_DrawFrame(&LcdA, 0, 0, 128, 64);   // frame
   u8g2_DrawFrame(&LcdB, 0, 0, 128, 64);   // frame
   u8g2_SetFont(&LcdA, u8g2_font_8x13B_tf);
   u8g2_SetFont(&LcdB, u8g2_font_8x13B_tf);
   sprintf(s, "Digital Audio");
   u8g2_DrawStr(&LcdA, 12, 20, s);      // title
   u8g2_DrawStr(&LcdB, 12, 20, s);      // title
   u8g2_SetFont(&LcdA, u8g2_font_6x10_tf);
   u8g2_SetFont(&LcdB, u8g2_font_6x10_tf);
   sprintf(s, "Software: v0.3");
   u8g2_DrawStr(&LcdA, 6, 36, s);
   u8g2_DrawStr(&LcdB, 6, 36, s);
   sprintf(s, "Git: %s", Git_VersionStr, Git_BranchStr);
   u8g2_DrawStr(&LcdA, 6, 46, s);
   u8g2_DrawStr(&LcdB, 6, 46, s);
   sprintf(s, "Date: %04u-%02u-%02u", Git_DateYear, Git_DateMonth, Git_DateDay);
   u8g2_DrawStr(&LcdA, 6, 56, s);
   u8g2_DrawStr(&LcdB, 6, 56, s);
   u8g2_SendBuffer(&LcdA); // transfer buffer content to LCD
   u8g2_SendBuffer(&LcdB); // transfer buffer content to LCD

   printf("----------------------------------------\n"
      "Digital Audio\n"
      "Git version: %s (%s)\n"
      "----------------------------------------\n",
      Git_VersionStr,
      Git_BranchStr
   );

  UI_Init();

  /* USER CODE END 2 */

  /* Infinite loop */
  /* USER CODE BEGIN WHILE */
   while (1)
   {
      static uint32_t Tick10msRef = 0;
      if (TickChk(&Tick10msRef, 10)) {  // execute every 10ms
         ShiftReg_Update();
         Kbd_Task();  // handle keyboard input and update state
         UI_EventProc(EV_UI_TICK_10MS);
      }

      static uint32_t Tick1secRef = 0;
      if (TickChk(&Tick1secRef, 1000)) {  // execute every 1s
         LD2_Toggle();
         UI_EventProc(EV_UI_TICK_1S);
         static uint8_t cnt = 0;
         cnt = (cnt + 1) % 8;
      }

      static uint32_t Tick100msRef = 0;
      if (TickChk(&Tick100msRef, 100)) {  // execute every 100ms
      }

      int16_t ch = Uart5_GetByte();
      if (ch != -1) {  // if data received
         char c = ch;
         static uint8_t PGA = 64;
         if (c == 'a') {
            printf("I2S RX buf:\n");
            for (size_t i = 0; i < I2S2_RXDMA_BUF_SAMPLE_CNT; i++) {
               printf("%d;%d\n", I2S2RxDmaBuf[i][0]/65536, I2S2RxDmaBuf[i][1]/65536);
            }
         } else if (c == ' ') {
            uint8_t d = 255;
            Usart2_TxBufWrite(&d, 1, 1);  // send trigger byte on USART2 to start ping-pong test
         } else if (c == 'd') {
            TLV320_AIC3204_DumpRegs();
         }else if (c == 'u') {
            if (PGA < 127-8) {
               PGA += 8;
               TlvWriteReg(CODEC_A, TLV_PAGE_0, 15, PGA);  // PGA_L
               TlvWriteReg(CODEC_A, TLV_PAGE_0, 16, PGA);  // PGA_R
               printf("PGA: %u\n", PGA);
            }
         }else if (c == 'j') {
            if (PGA >= 8) {
               PGA -= 8;
               TlvWriteReg(CODEC_A, TLV_PAGE_0, 15, PGA);  // PGA_L
               TlvWriteReg(CODEC_A, TLV_PAGE_0, 16, PGA);  // PGA_R
               printf("PGA: %u\n", PGA);
            }
         }else if (c == 't') { UI_EventProcKbd(0);
         }else if (c == 'z') { UI_EventProcKbd(1);
         }else if (c == 'h') { UI_EventProcKbd(2);
         }else if (c == 'o') { UI_EventProcKbd(3);
         }else if (c == 'i') { UI_EventProcKbd(4);
         }else if (c == 'k') { UI_EventProcKbd(5);
         }else if (c == 'f') {
            TlvWriteReg(CODEC_A, TLV_PAGE_0, 12, 0xF0);  // Enable ADC high-pass filter
         }
      }

      Usart2_DMA_Task(); // handle USART2 DMA rx/tx
      Usart3_DMA_Task(); // handle USART3 DMA rx/tx
      AudioDAC_Task(&AudioDac_A);  // handle audio data processing for Codec-A (I2S2)
      AudioDAC_Task(&AudioDac_B);  // handle audio data processing for Codec-B (I2S3)
      AudioADC_Task();      // handle audio data processing from I2S Rx buffer
      UI_CheckEvent();

    /* USER CODE END WHILE */

  }
}

void SystemClock_Config(void)
{
  LL_FLASH_SetLatency(LL_FLASH_LATENCY_3);
  while(LL_FLASH_GetLatency()!= LL_FLASH_LATENCY_3)
  {
  }

  LL_PWR_SetRegulVoltageScaling(LL_PWR_REGU_VOLTAGE_SCALE3);
  while (LL_PWR_IsActiveFlag_VOS() == 0)
  {
  }
  LL_RCC_HSE_Enable();

   /* Wait till HSE is ready */
  while(LL_RCC_HSE_IsReady() != 1)
  {
  }

  LL_RCC_PLL1_SetSource(LL_RCC_PLL1SOURCE_HSE);
  LL_RCC_PLL1_SetVCOInputRange(LL_RCC_PLLINPUTRANGE_8_16);
  LL_RCC_PLL1_SetVCOOutputRange(LL_RCC_PLLVCORANGE_WIDE);
  LL_RCC_PLL1_SetM(1);
  LL_RCC_PLL1_SetN(20);
  LL_RCC_PLL1_SetP(4);
  LL_RCC_PLL1_SetQ(10);
  LL_RCC_PLL1_SetR(2);
  LL_RCC_PLL1Q_Enable();
  LL_RCC_PLL1P_Enable();
  LL_RCC_PLL1_Enable();

   /* Wait till PLL is ready */
  while(LL_RCC_PLL1_IsReady() != 1)
  {
  }

  LL_RCC_SetSysClkSource(LL_RCC_SYS_CLKSOURCE_PLL1);

   /* Wait till System clock is ready */
  while(LL_RCC_GetSysClkSource() != LL_RCC_SYS_CLKSOURCE_STATUS_PLL1)
  {
  }

  LL_RCC_SetAHBPrescaler(LL_RCC_SYSCLK_DIV_1);
  LL_RCC_SetAPB1Prescaler(LL_RCC_APB1_DIV_1);
  LL_RCC_SetAPB2Prescaler(LL_RCC_APB2_DIV_1);
  LL_RCC_SetAPB3Prescaler(LL_RCC_APB3_DIV_1);

  LL_Init1msTick(80000000);

  LL_SetSystemCoreClock(80000000);
}

void PeriphCommonClock_Config(void)
{
  LL_RCC_PLL2_SetSource(LL_RCC_PLL2SOURCE_HSE);
  LL_RCC_PLL2_SetVCOInputRange(LL_RCC_PLLINPUTRANGE_8_16);
  LL_RCC_PLL2_SetVCOOutputRange(LL_RCC_PLLVCORANGE_WIDE);
  LL_RCC_PLL2_SetM(10);
  LL_RCC_PLL2_SetN(256);
  LL_RCC_PLL2_SetP(10);
  LL_RCC_PLL2_SetQ(10);
  LL_RCC_PLL2_SetR(2);
  LL_RCC_PLL2P_Enable();
  LL_RCC_PLL2_Enable();

   /* Wait till PLL is ready */
  while(LL_RCC_PLL2_IsReady() != 1)
  {
  }

  LL_RCC_PLL3_SetSource(LL_RCC_PLL3SOURCE_HSE);
  LL_RCC_PLL3_SetVCOInputRange(LL_RCC_PLLINPUTRANGE_8_16);
  LL_RCC_PLL3_SetVCOOutputRange(LL_RCC_PLLVCORANGE_WIDE);
  LL_RCC_PLL3_SetM(1);
  LL_RCC_PLL3_SetN(8);
  LL_RCC_PLL3_SetP(2);
  LL_RCC_PLL3_SetQ(4);
  LL_RCC_PLL3_SetR(4);
  LL_RCC_PLL3Q_Enable();
  LL_RCC_PLL3R_Enable();
  LL_RCC_PLL3_Enable();

   /* Wait till PLL is ready */
  while(LL_RCC_PLL3_IsReady() != 1)
  {
  }

}

static void MX_GPDMA1_Init(void)
{

  /* Peripheral clock enable */
  LL_AHB1_GRP1_EnableClock(LL_AHB1_GRP1_PERIPH_GPDMA1);

}

static void MX_GPDMA2_Init(void)
{

  /* Peripheral clock enable */
  LL_AHB1_GRP1_EnableClock(LL_AHB1_GRP1_PERIPH_GPDMA2);

}

static void MX_I2C1_Init(void)
{

  LL_I2C_InitTypeDef I2C_InitStruct = {0};

  LL_GPIO_InitTypeDef GPIO_InitStruct = {0};

  LL_RCC_SetI2CClockSource(LL_RCC_I2C1_CLKSOURCE_PLL3R);

  LL_AHB2_GRP1_EnableClock(LL_AHB2_GRP1_PERIPH_GPIOB);
  /**I2C1 GPIO Configuration
  PB6   ------> I2C1_SCL
  PB7   ------> I2C1_SDA
  */
  GPIO_InitStruct.Pin = LL_GPIO_PIN_6|LL_GPIO_PIN_7;
  GPIO_InitStruct.Mode = LL_GPIO_MODE_ALTERNATE;
  GPIO_InitStruct.Speed = LL_GPIO_SPEED_FREQ_LOW;
  GPIO_InitStruct.OutputType = LL_GPIO_OUTPUT_OPENDRAIN;
  GPIO_InitStruct.Pull = LL_GPIO_PULL_NO;
  GPIO_InitStruct.Alternate = LL_GPIO_AF_4;
  LL_GPIO_Init(GPIOB, &GPIO_InitStruct);

  /* Peripheral clock enable */
  LL_APB1_GRP1_EnableClock(LL_APB1_GRP1_PERIPH_I2C1);

  /** I2C Initialization
  */
  LL_I2C_EnableAutoEndMode(I2C1);
  LL_I2C_DisableOwnAddress2(I2C1);
  LL_I2C_DisableGeneralCall(I2C1);
  LL_I2C_EnableClockStretching(I2C1);
  I2C_InitStruct.PeripheralMode = LL_I2C_MODE_I2C;
  I2C_InitStruct.Timing = 0x00707CBB;
  I2C_InitStruct.AnalogFilter = LL_I2C_ANALOGFILTER_ENABLE;
  I2C_InitStruct.DigitalFilter = 0;
  I2C_InitStruct.OwnAddress1 = 0;
  I2C_InitStruct.TypeAcknowledge = LL_I2C_ACK;
  I2C_InitStruct.OwnAddrSize = LL_I2C_OWNADDRESS1_7BIT;
  LL_I2C_Init(I2C1, &I2C_InitStruct);
  LL_I2C_SetOwnAddress2(I2C1, 0, LL_I2C_OWNADDRESS2_NOMASK);

  /** I2C Fast mode Plus enable
  */
  LL_I2C_EnableFastModePlus(I2C1);

}

static void MX_I2C3_Init(void)
{

  LL_I2C_InitTypeDef I2C_InitStruct = {0};

  LL_GPIO_InitTypeDef GPIO_InitStruct = {0};

  LL_RCC_SetI2CClockSource(LL_RCC_I2C3_CLKSOURCE_PLL3R);

  LL_AHB2_GRP1_EnableClock(LL_AHB2_GRP1_PERIPH_GPIOC);
  LL_AHB2_GRP1_EnableClock(LL_AHB2_GRP1_PERIPH_GPIOA);
  /**I2C3 GPIO Configuration
  PC9   ------> I2C3_SDA
  PA8   ------> I2C3_SCL
  */
  GPIO_InitStruct.Pin = LL_GPIO_PIN_9;
  GPIO_InitStruct.Mode = LL_GPIO_MODE_ALTERNATE;
  GPIO_InitStruct.Speed = LL_GPIO_SPEED_FREQ_LOW;
  GPIO_InitStruct.OutputType = LL_GPIO_OUTPUT_OPENDRAIN;
  GPIO_InitStruct.Pull = LL_GPIO_PULL_NO;
  GPIO_InitStruct.Alternate = LL_GPIO_AF_4;
  LL_GPIO_Init(GPIOC, &GPIO_InitStruct);

  GPIO_InitStruct.Pin = LL_GPIO_PIN_8;
  GPIO_InitStruct.Mode = LL_GPIO_MODE_ALTERNATE;
  GPIO_InitStruct.Speed = LL_GPIO_SPEED_FREQ_LOW;
  GPIO_InitStruct.OutputType = LL_GPIO_OUTPUT_OPENDRAIN;
  GPIO_InitStruct.Pull = LL_GPIO_PULL_NO;
  GPIO_InitStruct.Alternate = LL_GPIO_AF_4;
  LL_GPIO_Init(GPIOA, &GPIO_InitStruct);

  /* Peripheral clock enable */
  LL_APB3_GRP1_EnableClock(LL_APB3_GRP1_PERIPH_I2C3);

  /** I2C Initialization
  */
  LL_I2C_EnableAutoEndMode(I2C3);
  LL_I2C_DisableOwnAddress2(I2C3);
  LL_I2C_DisableGeneralCall(I2C3);
  LL_I2C_EnableClockStretching(I2C3);
  I2C_InitStruct.PeripheralMode = LL_I2C_MODE_I2C;
  I2C_InitStruct.Timing = 0x00707CBB;
  I2C_InitStruct.AnalogFilter = LL_I2C_ANALOGFILTER_ENABLE;
  I2C_InitStruct.DigitalFilter = 0;
  I2C_InitStruct.OwnAddress1 = 0;
  I2C_InitStruct.TypeAcknowledge = LL_I2C_ACK;
  I2C_InitStruct.OwnAddrSize = LL_I2C_OWNADDRESS1_7BIT;
  LL_I2C_Init(I2C3, &I2C_InitStruct);
  LL_I2C_SetOwnAddress2(I2C3, 0, LL_I2C_OWNADDRESS2_NOMASK);

  /** I2C Fast mode Plus enable
  */
  LL_I2C_EnableFastModePlus(I2C3);

}

static void MX_I2S2_Init(void)
{

  /* USER CODE BEGIN I2S2_Init 0 */

   // WARNING
   // Remove the second redefinition of NodeConfig after Cube MX code generation.
   LL_DMA_InitNodeTypeDef NodeConfig = {0};

  /* USER CODE END I2S2_Init 0 */

  LL_I2S_InitTypeDef I2S_InitStruct = {0};

  LL_GPIO_InitTypeDef GPIO_InitStruct = {0};
  LL_DMA_InitLinkedListTypeDef DMA_InitLinkedListStruct = {0};

  LL_RCC_SetSPIClockSource(LL_RCC_SPI2_CLKSOURCE_PLL2P);

  /* Peripheral clock enable */
  LL_APB1_GRP1_EnableClock(LL_APB1_GRP1_PERIPH_SPI2);

  LL_AHB2_GRP1_EnableClock(LL_AHB2_GRP1_PERIPH_GPIOC);
  LL_AHB2_GRP1_EnableClock(LL_AHB2_GRP1_PERIPH_GPIOB);
  /**I2S2 GPIO Configuration
  PC2   ------> I2S2_SDI
  PB12   ------> I2S2_WS
  PB13   ------> I2S2_CK
  PB15   ------> I2S2_SDO
  PC6   ------> I2S2_MCK
  */
  GPIO_InitStruct.Pin = LL_GPIO_PIN_2;
  GPIO_InitStruct.Mode = LL_GPIO_MODE_ALTERNATE;
  GPIO_InitStruct.Speed = LL_GPIO_SPEED_FREQ_MEDIUM;
  GPIO_InitStruct.OutputType = LL_GPIO_OUTPUT_PUSHPULL;
  GPIO_InitStruct.Pull = LL_GPIO_PULL_NO;
  GPIO_InitStruct.Alternate = LL_GPIO_AF_5;
  LL_GPIO_Init(GPIOC, &GPIO_InitStruct);

  GPIO_InitStruct.Pin = LL_GPIO_PIN_12|LL_GPIO_PIN_13|LL_GPIO_PIN_15;
  GPIO_InitStruct.Mode = LL_GPIO_MODE_ALTERNATE;
  GPIO_InitStruct.Speed = LL_GPIO_SPEED_FREQ_MEDIUM;
  GPIO_InitStruct.OutputType = LL_GPIO_OUTPUT_PUSHPULL;
  GPIO_InitStruct.Pull = LL_GPIO_PULL_NO;
  GPIO_InitStruct.Alternate = LL_GPIO_AF_5;
  LL_GPIO_Init(GPIOB, &GPIO_InitStruct);

  GPIO_InitStruct.Pin = LL_GPIO_PIN_6;
  GPIO_InitStruct.Mode = LL_GPIO_MODE_ALTERNATE;
  GPIO_InitStruct.Speed = LL_GPIO_SPEED_FREQ_HIGH;
  GPIO_InitStruct.OutputType = LL_GPIO_OUTPUT_PUSHPULL;
  GPIO_InitStruct.Pull = LL_GPIO_PULL_NO;
  GPIO_InitStruct.Alternate = LL_GPIO_AF_5;
  LL_GPIO_Init(GPIOC, &GPIO_InitStruct);

  /* I2S2 DMA Init */

  /* GPDMA2_REQUEST_SPI2_RX Init */
  NodeConfig.SrcAddress        = (uint32_t)LL_SPI_DMA_GetRxRegAddr(SPI2);
  NodeConfig.DestAddress       = (uint32_t)&I2S2RxDmaBuf;
  NodeConfig.BlkDataLength     = sizeof(I2S2RxDmaBuf);

  NodeConfig.DestAllocatedPort = LL_DMA_DEST_ALLOCATED_PORT1;
  NodeConfig.DestHWordExchange = LL_DMA_DEST_HALFWORD_PRESERVE;
  NodeConfig.DestByteExchange = LL_DMA_DEST_BYTE_PRESERVE;
  NodeConfig.DestBurstLength = 1;
  NodeConfig.DestIncMode = LL_DMA_DEST_INCREMENT;
  NodeConfig.DestDataWidth = LL_DMA_DEST_DATAWIDTH_WORD;
  NodeConfig.SrcAllocatedPort = LL_DMA_SRC_ALLOCATED_PORT0;
  NodeConfig.SrcByteExchange = LL_DMA_SRC_BYTE_PRESERVE;
  NodeConfig.DataAlignment = LL_DMA_DATA_ALIGN_ZEROPADD;
  NodeConfig.SrcBurstLength = 1;
  NodeConfig.SrcIncMode = LL_DMA_SRC_FIXED;
  NodeConfig.SrcDataWidth = LL_DMA_SRC_DATAWIDTH_WORD;
  NodeConfig.TransferEventMode = LL_DMA_TCEM_BLK_TRANSFER;
  NodeConfig.Mode = LL_DMA_NORMAL;
  NodeConfig.TriggerPolarity = LL_DMA_TRIG_POLARITY_MASKED;
  NodeConfig.BlkHWRequest = LL_DMA_HWREQUEST_SINGLEBURST;
  NodeConfig.Direction = LL_DMA_DIRECTION_PERIPH_TO_MEMORY;
  NodeConfig.Request = LL_GPDMA2_REQUEST_SPI2_RX;
  NodeConfig.UpdateRegisters = (LL_DMA_UPDATE_CTR1 | LL_DMA_UPDATE_CTR2 | LL_DMA_UPDATE_CBR1 | LL_DMA_UPDATE_CSAR | LL_DMA_UPDATE_CDAR | LL_DMA_UPDATE_CTR3 | LL_DMA_UPDATE_CBR2 | LL_DMA_UPDATE_CLLR);
  NodeConfig.NodeType = LL_DMA_GPDMA_LINEAR_NODE;
  LL_DMA_CreateLinkNode(&NodeConfig, &Node_GPDMA2_Channel1);

  LL_DMA_ConnectLinkNode(&Node_GPDMA2_Channel1, LL_DMA_CLLR_OFFSET5, &Node_GPDMA2_Channel1, LL_DMA_CLLR_OFFSET5);

  /* Next function call is commented because it will not compile as is. The Node structure address has to be cast to an unsigned int (uint32_t)pNode_DMAxCHy */
  /*

  */
  LL_DMA_SetLinkedListBaseAddr(GPDMA2, LL_DMA_CHANNEL_1, (uint32_t)&Node_GPDMA2_Channel1);

  DMA_InitLinkedListStruct.Priority = LL_DMA_LOW_PRIORITY_LOW_WEIGHT;
  DMA_InitLinkedListStruct.LinkStepMode = LL_DMA_LSM_FULL_EXECUTION;
  DMA_InitLinkedListStruct.LinkAllocatedPort = LL_DMA_LINK_ALLOCATED_PORT1;
  DMA_InitLinkedListStruct.TransferEventMode = LL_DMA_TCEM_BLK_TRANSFER;
  LL_DMA_List_Init(GPDMA2, LL_DMA_CHANNEL_1, &DMA_InitLinkedListStruct);

  /* GPDMA2_REQUEST_SPI2_TX Init */
  NodeConfig.SrcAddress        = (uint32_t)&I2S2TxDmaBuf;
  NodeConfig.DestAddress       = (uint32_t)LL_SPI_DMA_GetTxRegAddr(SPI2);
  NodeConfig.BlkDataLength     = sizeof(I2S2TxDmaBuf);

  NodeConfig.DestAllocatedPort = LL_DMA_DEST_ALLOCATED_PORT0;
  NodeConfig.DestHWordExchange = LL_DMA_DEST_HALFWORD_PRESERVE;
  NodeConfig.DestByteExchange = LL_DMA_DEST_BYTE_PRESERVE;
  NodeConfig.DestBurstLength = 1;
  NodeConfig.DestIncMode = LL_DMA_DEST_FIXED;
  NodeConfig.DestDataWidth = LL_DMA_DEST_DATAWIDTH_WORD;
  NodeConfig.SrcAllocatedPort = LL_DMA_SRC_ALLOCATED_PORT1;
  NodeConfig.SrcByteExchange = LL_DMA_SRC_BYTE_PRESERVE;
  NodeConfig.DataAlignment = LL_DMA_DATA_ALIGN_ZEROPADD;
  NodeConfig.SrcBurstLength = 1;
  NodeConfig.SrcIncMode = LL_DMA_SRC_INCREMENT;
  NodeConfig.SrcDataWidth = LL_DMA_SRC_DATAWIDTH_WORD;
  NodeConfig.TransferEventMode = LL_DMA_TCEM_BLK_TRANSFER;
  NodeConfig.Mode = LL_DMA_NORMAL;
  NodeConfig.TriggerPolarity = LL_DMA_TRIG_POLARITY_MASKED;
  NodeConfig.BlkHWRequest = LL_DMA_HWREQUEST_SINGLEBURST;
  NodeConfig.Direction = LL_DMA_DIRECTION_MEMORY_TO_PERIPH;
  NodeConfig.Request = LL_GPDMA2_REQUEST_SPI2_TX;
  NodeConfig.UpdateRegisters = (LL_DMA_UPDATE_CTR1 | LL_DMA_UPDATE_CTR2 | LL_DMA_UPDATE_CBR1 | LL_DMA_UPDATE_CSAR | LL_DMA_UPDATE_CDAR | LL_DMA_UPDATE_CTR3 | LL_DMA_UPDATE_CBR2 | LL_DMA_UPDATE_CLLR);
  NodeConfig.NodeType = LL_DMA_GPDMA_LINEAR_NODE;
  LL_DMA_CreateLinkNode(&NodeConfig, &Node_GPDMA2_Channel0);

  LL_DMA_ConnectLinkNode(&Node_GPDMA2_Channel0, LL_DMA_CLLR_OFFSET5, &Node_GPDMA2_Channel0, LL_DMA_CLLR_OFFSET5);

  /* Next function call is commented because it will not compile as is. The Node structure address has to be cast to an unsigned int (uint32_t)pNode_DMAxCHy */
  /*

  */
  LL_DMA_SetLinkedListBaseAddr(GPDMA2, LL_DMA_CHANNEL_0, (uint32_t)&Node_GPDMA2_Channel0);

  DMA_InitLinkedListStruct.Priority = LL_DMA_LOW_PRIORITY_LOW_WEIGHT;
  DMA_InitLinkedListStruct.LinkStepMode = LL_DMA_LSM_FULL_EXECUTION;
  DMA_InitLinkedListStruct.LinkAllocatedPort = LL_DMA_LINK_ALLOCATED_PORT1;
  DMA_InitLinkedListStruct.TransferEventMode = LL_DMA_TCEM_BLK_TRANSFER;
  LL_DMA_List_Init(GPDMA2, LL_DMA_CHANNEL_0, &DMA_InitLinkedListStruct);

  /* USER CODE BEGIN I2S2_Init 1 */

  LL_DMA_ConfigLinkUpdate(GPDMA2, LL_DMA_CHANNEL_1, LL_DMA_UPDATE_CTR1 | LL_DMA_UPDATE_CTR2 |LL_DMA_UPDATE_CBR1 | LL_DMA_UPDATE_CSAR | LL_DMA_UPDATE_CDAR | LL_DMA_UPDATE_CLLR, (uint32_t)&Node_GPDMA2_Channel1);
  LL_DMA_EnableChannel(GPDMA2, LL_DMA_CHANNEL_1);
  LL_DMA_SetLinkedListAddrOffset(GPDMA2, LL_DMA_CHANNEL_1, LL_DMA_CLLR_OFFSET5);
  LL_I2S_EnableDMAReq_RX(SPI2);

  LL_DMA_ConfigLinkUpdate(GPDMA2, LL_DMA_CHANNEL_0, LL_DMA_UPDATE_CTR1 | LL_DMA_UPDATE_CTR2 |LL_DMA_UPDATE_CBR1 | LL_DMA_UPDATE_CSAR | LL_DMA_UPDATE_CDAR | LL_DMA_UPDATE_CLLR, (uint32_t)&Node_GPDMA2_Channel0);
  LL_DMA_EnableChannel(GPDMA2, LL_DMA_CHANNEL_0);
  LL_DMA_SetLinkedListAddrOffset(GPDMA2, LL_DMA_CHANNEL_0, LL_DMA_CLLR_OFFSET5);
  LL_I2S_EnableDMAReq_TX(SPI2);

  /* USER CODE END I2S2_Init 1 */
  I2S_InitStruct.Mode = LL_I2S_MODE_MASTER_FULL_DUPLEX;
  I2S_InitStruct.Standard = LL_I2S_STANDARD_PHILIPS;
  I2S_InitStruct.DataFormat = LL_I2S_DATAFORMAT_32B;
  I2S_InitStruct.MCLKOutput = LL_I2S_MCLK_OUTPUT_ENABLE;
  I2S_InitStruct.AudioFreq = 32000;
  I2S_InitStruct.ClockPolarity = LL_I2S_POLARITY_LOW;
  LL_I2S_Init(SPI2, &I2S_InitStruct);
  /* USER CODE BEGIN I2S2_Init 2 */

  LL_I2S_Enable(SPI2);
  LL_I2S_StartTransfer(SPI2);

  /* USER CODE END I2S2_Init 2 */

}

static void MX_I2S3_Init(void)
{

  /* USER CODE BEGIN I2S3_Init 0 */

   // WARNING
   // Remove the second redefinition of NodeConfig after Cube MX code generation.
   LL_DMA_InitNodeTypeDef NodeConfig = {0};

  /* USER CODE END I2S3_Init 0 */

  LL_I2S_InitTypeDef I2S_InitStruct = {0};

  LL_GPIO_InitTypeDef GPIO_InitStruct = {0};
  LL_DMA_InitLinkedListTypeDef DMA_InitLinkedListStruct = {0};

  LL_RCC_SetSPIClockSource(LL_RCC_SPI3_CLKSOURCE_PLL2P);

  /* Peripheral clock enable */
  LL_APB1_GRP1_EnableClock(LL_APB1_GRP1_PERIPH_SPI3);

  LL_AHB2_GRP1_EnableClock(LL_AHB2_GRP1_PERIPH_GPIOC);
  LL_AHB2_GRP1_EnableClock(LL_AHB2_GRP1_PERIPH_GPIOA);
  LL_AHB2_GRP1_EnableClock(LL_AHB2_GRP1_PERIPH_GPIOB);
  /**I2S3 GPIO Configuration
  PC7   ------> I2S3_MCK
  PA15(JTDI)   ------> I2S3_WS
  PC10   ------> I2S3_CK
  PB4(NJTRST)   ------> I2S3_SDI
  PB5   ------> I2S3_SDO
  */
  GPIO_InitStruct.Pin = LL_GPIO_PIN_7;
  GPIO_InitStruct.Mode = LL_GPIO_MODE_ALTERNATE;
  GPIO_InitStruct.Speed = LL_GPIO_SPEED_FREQ_HIGH;
  GPIO_InitStruct.OutputType = LL_GPIO_OUTPUT_PUSHPULL;
  GPIO_InitStruct.Pull = LL_GPIO_PULL_NO;
  GPIO_InitStruct.Alternate = LL_GPIO_AF_6;
  LL_GPIO_Init(GPIOC, &GPIO_InitStruct);

  GPIO_InitStruct.Pin = LL_GPIO_PIN_15;
  GPIO_InitStruct.Mode = LL_GPIO_MODE_ALTERNATE;
  GPIO_InitStruct.Speed = LL_GPIO_SPEED_FREQ_MEDIUM;
  GPIO_InitStruct.OutputType = LL_GPIO_OUTPUT_PUSHPULL;
  GPIO_InitStruct.Pull = LL_GPIO_PULL_NO;
  GPIO_InitStruct.Alternate = LL_GPIO_AF_6;
  LL_GPIO_Init(GPIOA, &GPIO_InitStruct);

  GPIO_InitStruct.Pin = LL_GPIO_PIN_10;
  GPIO_InitStruct.Mode = LL_GPIO_MODE_ALTERNATE;
  GPIO_InitStruct.Speed = LL_GPIO_SPEED_FREQ_MEDIUM;
  GPIO_InitStruct.OutputType = LL_GPIO_OUTPUT_PUSHPULL;
  GPIO_InitStruct.Pull = LL_GPIO_PULL_NO;
  GPIO_InitStruct.Alternate = LL_GPIO_AF_6;
  LL_GPIO_Init(GPIOC, &GPIO_InitStruct);

  GPIO_InitStruct.Pin = LL_GPIO_PIN_4;
  GPIO_InitStruct.Mode = LL_GPIO_MODE_ALTERNATE;
  GPIO_InitStruct.Speed = LL_GPIO_SPEED_FREQ_MEDIUM;
  GPIO_InitStruct.OutputType = LL_GPIO_OUTPUT_PUSHPULL;
  GPIO_InitStruct.Pull = LL_GPIO_PULL_NO;
  GPIO_InitStruct.Alternate = LL_GPIO_AF_6;
  LL_GPIO_Init(GPIOB, &GPIO_InitStruct);

  GPIO_InitStruct.Pin = LL_GPIO_PIN_5;
  GPIO_InitStruct.Mode = LL_GPIO_MODE_ALTERNATE;
  GPIO_InitStruct.Speed = LL_GPIO_SPEED_FREQ_MEDIUM;
  GPIO_InitStruct.OutputType = LL_GPIO_OUTPUT_PUSHPULL;
  GPIO_InitStruct.Pull = LL_GPIO_PULL_NO;
  GPIO_InitStruct.Alternate = LL_GPIO_AF_7;
  LL_GPIO_Init(GPIOB, &GPIO_InitStruct);

  /* I2S3 DMA Init */

  /* GPDMA2_REQUEST_SPI3_RX Init */
  NodeConfig.SrcAddress        = (uint32_t)LL_SPI_DMA_GetRxRegAddr(SPI3);
  NodeConfig.DestAddress       = (uint32_t)&I2S3RxDmaBuf;
  NodeConfig.BlkDataLength     = sizeof(I2S3RxDmaBuf);

  NodeConfig.DestAllocatedPort = LL_DMA_DEST_ALLOCATED_PORT1;
  NodeConfig.DestHWordExchange = LL_DMA_DEST_HALFWORD_PRESERVE;
  NodeConfig.DestByteExchange = LL_DMA_DEST_BYTE_PRESERVE;
  NodeConfig.DestBurstLength = 1;
  NodeConfig.DestIncMode = LL_DMA_DEST_INCREMENT;
  NodeConfig.DestDataWidth = LL_DMA_DEST_DATAWIDTH_WORD;
  NodeConfig.SrcAllocatedPort = LL_DMA_SRC_ALLOCATED_PORT0;
  NodeConfig.SrcByteExchange = LL_DMA_SRC_BYTE_PRESERVE;
  NodeConfig.DataAlignment = LL_DMA_DATA_ALIGN_ZEROPADD;
  NodeConfig.SrcBurstLength = 1;
  NodeConfig.SrcIncMode = LL_DMA_SRC_FIXED;
  NodeConfig.SrcDataWidth = LL_DMA_SRC_DATAWIDTH_WORD;
  NodeConfig.TransferEventMode = LL_DMA_TCEM_BLK_TRANSFER;
  NodeConfig.Mode = LL_DMA_NORMAL;
  NodeConfig.TriggerPolarity = LL_DMA_TRIG_POLARITY_MASKED;
  NodeConfig.BlkHWRequest = LL_DMA_HWREQUEST_SINGLEBURST;
  NodeConfig.Direction = LL_DMA_DIRECTION_PERIPH_TO_MEMORY;
  NodeConfig.Request = LL_GPDMA2_REQUEST_SPI3_RX;
  NodeConfig.UpdateRegisters = (LL_DMA_UPDATE_CTR1 | LL_DMA_UPDATE_CTR2 | LL_DMA_UPDATE_CBR1 | LL_DMA_UPDATE_CSAR | LL_DMA_UPDATE_CDAR | LL_DMA_UPDATE_CTR3 | LL_DMA_UPDATE_CBR2 | LL_DMA_UPDATE_CLLR);
  NodeConfig.NodeType = LL_DMA_GPDMA_LINEAR_NODE;
  LL_DMA_CreateLinkNode(&NodeConfig, &Node_GPDMA2_Channel3);

  LL_DMA_ConnectLinkNode(&Node_GPDMA2_Channel3, LL_DMA_CLLR_OFFSET5, &Node_GPDMA2_Channel3, LL_DMA_CLLR_OFFSET5);

  /* Next function call is commented because it will not compile as is. The Node structure address has to be cast to an unsigned int (uint32_t)pNode_DMAxCHy */
  /*

  */
  LL_DMA_SetLinkedListBaseAddr(GPDMA2, LL_DMA_CHANNEL_3, (uint32_t)&Node_GPDMA2_Channel3);

  DMA_InitLinkedListStruct.Priority = LL_DMA_LOW_PRIORITY_LOW_WEIGHT;
  DMA_InitLinkedListStruct.LinkStepMode = LL_DMA_LSM_FULL_EXECUTION;
  DMA_InitLinkedListStruct.LinkAllocatedPort = LL_DMA_LINK_ALLOCATED_PORT1;
  DMA_InitLinkedListStruct.TransferEventMode = LL_DMA_TCEM_BLK_TRANSFER;
  LL_DMA_List_Init(GPDMA2, LL_DMA_CHANNEL_3, &DMA_InitLinkedListStruct);

  /* GPDMA2_REQUEST_SPI3_TX Init */
  NodeConfig.SrcAddress        = (uint32_t)&I2S3TxDmaBuf;
  NodeConfig.DestAddress       = (uint32_t)LL_SPI_DMA_GetTxRegAddr(SPI3);
  NodeConfig.BlkDataLength     = sizeof(I2S3TxDmaBuf);

  NodeConfig.DestAllocatedPort = LL_DMA_DEST_ALLOCATED_PORT0;
  NodeConfig.DestHWordExchange = LL_DMA_DEST_HALFWORD_PRESERVE;
  NodeConfig.DestByteExchange = LL_DMA_DEST_BYTE_PRESERVE;
  NodeConfig.DestBurstLength = 1;
  NodeConfig.DestIncMode = LL_DMA_DEST_FIXED;
  NodeConfig.DestDataWidth = LL_DMA_DEST_DATAWIDTH_WORD;
  NodeConfig.SrcAllocatedPort = LL_DMA_SRC_ALLOCATED_PORT1;
  NodeConfig.SrcByteExchange = LL_DMA_SRC_BYTE_PRESERVE;
  NodeConfig.DataAlignment = LL_DMA_DATA_ALIGN_ZEROPADD;
  NodeConfig.SrcBurstLength = 1;
  NodeConfig.SrcIncMode = LL_DMA_SRC_INCREMENT;
  NodeConfig.SrcDataWidth = LL_DMA_SRC_DATAWIDTH_WORD;
  NodeConfig.TransferEventMode = LL_DMA_TCEM_BLK_TRANSFER;
  NodeConfig.Mode = LL_DMA_NORMAL;
  NodeConfig.TriggerPolarity = LL_DMA_TRIG_POLARITY_MASKED;
  NodeConfig.BlkHWRequest = LL_DMA_HWREQUEST_SINGLEBURST;
  NodeConfig.Direction = LL_DMA_DIRECTION_MEMORY_TO_PERIPH;
  NodeConfig.Request = LL_GPDMA2_REQUEST_SPI3_TX;
  NodeConfig.UpdateRegisters = (LL_DMA_UPDATE_CTR1 | LL_DMA_UPDATE_CTR2 | LL_DMA_UPDATE_CBR1 | LL_DMA_UPDATE_CSAR | LL_DMA_UPDATE_CDAR | LL_DMA_UPDATE_CTR3 | LL_DMA_UPDATE_CBR2 | LL_DMA_UPDATE_CLLR);
  NodeConfig.NodeType = LL_DMA_GPDMA_LINEAR_NODE;
  LL_DMA_CreateLinkNode(&NodeConfig, &Node_GPDMA2_Channel2);

  LL_DMA_ConnectLinkNode(&Node_GPDMA2_Channel2, LL_DMA_CLLR_OFFSET5, &Node_GPDMA2_Channel2, LL_DMA_CLLR_OFFSET5);

  /* Next function call is commented because it will not compile as is. The Node structure address has to be cast to an unsigned int (uint32_t)pNode_DMAxCHy */
  /*

  */
  LL_DMA_SetLinkedListBaseAddr(GPDMA2, LL_DMA_CHANNEL_2, (uint32_t)&Node_GPDMA2_Channel2);

  DMA_InitLinkedListStruct.Priority = LL_DMA_LOW_PRIORITY_LOW_WEIGHT;
  DMA_InitLinkedListStruct.LinkStepMode = LL_DMA_LSM_FULL_EXECUTION;
  DMA_InitLinkedListStruct.LinkAllocatedPort = LL_DMA_LINK_ALLOCATED_PORT1;
  DMA_InitLinkedListStruct.TransferEventMode = LL_DMA_TCEM_BLK_TRANSFER;
  LL_DMA_List_Init(GPDMA2, LL_DMA_CHANNEL_2, &DMA_InitLinkedListStruct);

  /* USER CODE BEGIN I2S3_Init 1 */

  LL_DMA_ConfigLinkUpdate(GPDMA2, LL_DMA_CHANNEL_3, LL_DMA_UPDATE_CTR1 | LL_DMA_UPDATE_CTR2 |LL_DMA_UPDATE_CBR1 | LL_DMA_UPDATE_CSAR | LL_DMA_UPDATE_CDAR | LL_DMA_UPDATE_CLLR, (uint32_t)&Node_GPDMA2_Channel3);
  LL_DMA_EnableChannel(GPDMA2, LL_DMA_CHANNEL_3);
  LL_DMA_SetLinkedListAddrOffset(GPDMA2, LL_DMA_CHANNEL_3, LL_DMA_CLLR_OFFSET5);
  LL_I2S_EnableDMAReq_RX(SPI3);

  LL_DMA_ConfigLinkUpdate(GPDMA2, LL_DMA_CHANNEL_2, LL_DMA_UPDATE_CTR1 | LL_DMA_UPDATE_CTR2 |LL_DMA_UPDATE_CBR1 | LL_DMA_UPDATE_CSAR | LL_DMA_UPDATE_CDAR | LL_DMA_UPDATE_CLLR, (uint32_t)&Node_GPDMA2_Channel2);
  LL_DMA_EnableChannel(GPDMA2, LL_DMA_CHANNEL_2);
  LL_DMA_SetLinkedListAddrOffset(GPDMA2, LL_DMA_CHANNEL_2, LL_DMA_CLLR_OFFSET5);
  LL_I2S_EnableDMAReq_TX(SPI3);

  /* USER CODE END I2S3_Init 1 */
  I2S_InitStruct.Mode = LL_I2S_MODE_MASTER_FULL_DUPLEX;
  I2S_InitStruct.Standard = LL_I2S_STANDARD_PHILIPS;
  I2S_InitStruct.DataFormat = LL_I2S_DATAFORMAT_32B;
  I2S_InitStruct.MCLKOutput = LL_I2S_MCLK_OUTPUT_ENABLE;
  I2S_InitStruct.AudioFreq = 32000;
  I2S_InitStruct.ClockPolarity = LL_I2S_POLARITY_LOW;
  LL_I2S_Init(SPI3, &I2S_InitStruct);
  /* USER CODE BEGIN I2S3_Init 2 */

  LL_I2S_Enable(SPI3);
  LL_I2S_StartTransfer(SPI3);

  /* USER CODE END I2S3_Init 2 */

}

static void MX_ICACHE_Init(void)
{

  /** Enable instruction cache (default 2-ways set associative cache)
  */
  LL_ICACHE_Enable();

}

static void MX_SPI1_Init(void)
{

  LL_SPI_InitTypeDef SPI_InitStruct = {0};

  LL_GPIO_InitTypeDef GPIO_InitStruct = {0};

  LL_RCC_SetSPIClockSource(LL_RCC_SPI1_CLKSOURCE_PLL1Q);

  /* Peripheral clock enable */
  LL_APB2_GRP1_EnableClock(LL_APB2_GRP1_PERIPH_SPI1);

  LL_AHB2_GRP1_EnableClock(LL_AHB2_GRP1_PERIPH_GPIOA);
  /**SPI1 GPIO Configuration
  PA5   ------> SPI1_SCK
  PA7   ------> SPI1_MOSI
  */
  GPIO_InitStruct.Pin = LL_GPIO_PIN_5|LL_GPIO_PIN_7;
  GPIO_InitStruct.Mode = LL_GPIO_MODE_ALTERNATE;
  GPIO_InitStruct.Speed = LL_GPIO_SPEED_FREQ_MEDIUM;
  GPIO_InitStruct.OutputType = LL_GPIO_OUTPUT_PUSHPULL;
  GPIO_InitStruct.Pull = LL_GPIO_PULL_NO;
  GPIO_InitStruct.Alternate = LL_GPIO_AF_5;
  LL_GPIO_Init(GPIOA, &GPIO_InitStruct);

  /* SPI1 parameter configuration*/
  SPI_InitStruct.TransferDirection = LL_SPI_SIMPLEX_TX;
  SPI_InitStruct.Mode = LL_SPI_MODE_MASTER;
  SPI_InitStruct.DataWidth = LL_SPI_DATAWIDTH_8BIT;
  SPI_InitStruct.ClockPolarity = LL_SPI_POLARITY_HIGH;
  SPI_InitStruct.ClockPhase = LL_SPI_PHASE_2EDGE;
  SPI_InitStruct.NSS = LL_SPI_NSS_SOFT;
  SPI_InitStruct.BaudRate = LL_SPI_BAUDRATEPRESCALER_DIV8;
  SPI_InitStruct.BitOrder = LL_SPI_MSB_FIRST;
  SPI_InitStruct.CRCCalculation = LL_SPI_CRCCALCULATION_DISABLE;
  SPI_InitStruct.CRCPoly = 0x7;
  LL_SPI_Init(SPI1, &SPI_InitStruct);
  LL_SPI_SetStandard(SPI1, LL_SPI_PROTOCOL_MOTOROLA);
  LL_SPI_DisableNSSPulseMgt(SPI1);

}

static void MX_TIM2_Init(void)
{

  LL_TIM_InitTypeDef TIM_InitStruct = {0};

  /* Peripheral clock enable */
  LL_APB1_GRP1_EnableClock(LL_APB1_GRP1_PERIPH_TIM2);

  TIM_InitStruct.Prescaler = 39999;
  TIM_InitStruct.CounterMode = LL_TIM_COUNTERMODE_UP;
  TIM_InitStruct.Autoreload = 4294967295;
  TIM_InitStruct.ClockDivision = LL_TIM_CLOCKDIVISION_DIV1;
  LL_TIM_Init(TIM2, &TIM_InitStruct);
  LL_TIM_DisableARRPreload(TIM2);
  LL_TIM_SetClockSource(TIM2, LL_TIM_CLOCKSOURCE_INTERNAL);
  LL_TIM_SetTriggerOutput(TIM2, LL_TIM_TRGO_RESET);
  LL_TIM_DisableMasterSlaveMode(TIM2);

}

static void MX_TIM5_Init(void)
{

  LL_TIM_InitTypeDef TIM_InitStruct = {0};

  /* Peripheral clock enable */
  LL_APB1_GRP1_EnableClock(LL_APB1_GRP1_PERIPH_TIM5);

  TIM_InitStruct.Prescaler = 79;
  TIM_InitStruct.CounterMode = LL_TIM_COUNTERMODE_UP;
  TIM_InitStruct.Autoreload = 4294967295;
  TIM_InitStruct.ClockDivision = LL_TIM_CLOCKDIVISION_DIV1;
  LL_TIM_Init(TIM5, &TIM_InitStruct);
  LL_TIM_DisableARRPreload(TIM5);
  LL_TIM_SetClockSource(TIM5, LL_TIM_CLOCKSOURCE_INTERNAL);
  LL_TIM_SetTriggerOutput(TIM5, LL_TIM_TRGO_RESET);
  LL_TIM_DisableMasterSlaveMode(TIM5);

}

static void MX_UART5_Init(void)
{

  LL_USART_InitTypeDef UART_InitStruct = {0};

  LL_GPIO_InitTypeDef GPIO_InitStruct = {0};

  LL_RCC_SetUARTClockSource(LL_RCC_UART5_CLKSOURCE_PLL3Q);

  /* Peripheral clock enable */
  LL_APB1_GRP1_EnableClock(LL_APB1_GRP1_PERIPH_UART5);

  LL_AHB2_GRP1_EnableClock(LL_AHB2_GRP1_PERIPH_GPIOC);
  LL_AHB2_GRP1_EnableClock(LL_AHB2_GRP1_PERIPH_GPIOD);
  /**UART5 GPIO Configuration
  PC12   ------> UART5_TX
  PD2   ------> UART5_RX
  */
  GPIO_InitStruct.Pin = LL_GPIO_PIN_12;
  GPIO_InitStruct.Mode = LL_GPIO_MODE_ALTERNATE;
  GPIO_InitStruct.Speed = LL_GPIO_SPEED_FREQ_LOW;
  GPIO_InitStruct.OutputType = LL_GPIO_OUTPUT_PUSHPULL;
  GPIO_InitStruct.Pull = LL_GPIO_PULL_NO;
  GPIO_InitStruct.Alternate = LL_GPIO_AF_8;
  LL_GPIO_Init(GPIOC, &GPIO_InitStruct);

  GPIO_InitStruct.Pin = LL_GPIO_PIN_2;
  GPIO_InitStruct.Mode = LL_GPIO_MODE_ALTERNATE;
  GPIO_InitStruct.Speed = LL_GPIO_SPEED_FREQ_LOW;
  GPIO_InitStruct.OutputType = LL_GPIO_OUTPUT_PUSHPULL;
  GPIO_InitStruct.Pull = LL_GPIO_PULL_NO;
  GPIO_InitStruct.Alternate = LL_GPIO_AF_8;
  LL_GPIO_Init(GPIOD, &GPIO_InitStruct);

  /* UART5 interrupt Init */
  NVIC_SetPriority(UART5_IRQn, NVIC_EncodePriority(NVIC_GetPriorityGrouping(),0, 0));
  NVIC_EnableIRQ(UART5_IRQn);

  UART_InitStruct.BaudRate = 115200;
  UART_InitStruct.DataWidth = LL_USART_DATAWIDTH_8B;
  UART_InitStruct.StopBits = LL_USART_STOPBITS_1;
  UART_InitStruct.Parity = LL_USART_PARITY_NONE;
  UART_InitStruct.TransferDirection = LL_USART_DIRECTION_TX_RX;
  UART_InitStruct.HardwareFlowControl = LL_USART_HWCONTROL_NONE;
  UART_InitStruct.OverSampling = LL_USART_OVERSAMPLING_16;
  LL_USART_Init(UART5, &UART_InitStruct);
  LL_USART_ConfigAsyncMode(UART5);
  LL_USART_Enable(UART5);

}

static void MX_USART2_UART_Init(void)
{

  /* USER CODE BEGIN USART2_Init 0 */

   // WARNING
   // Remove the second redefinition of NodeConfig after Cube MX code generation.
   LL_DMA_InitNodeTypeDef NodeConfig = {0};

   NodeConfig.SrcAddress        = (uint32_t)LL_USART_DMA_GetRegAddr(USART2, LL_USART_DMA_REG_DATA_RECEIVE);
   NodeConfig.DestAddress       = (uint32_t)&Usart2RxDmaBuf;
   NodeConfig.BlkDataLength     = ARRAY_COUNT(Usart2RxDmaBuf);

  /* USER CODE END USART2_Init 0 */

  LL_USART_InitTypeDef USART_InitStruct = {0};

  LL_GPIO_InitTypeDef GPIO_InitStruct = {0};
  LL_DMA_InitLinkedListTypeDef DMA_InitLinkedListStruct = {0};
  LL_DMA_InitTypeDef DMA_InitStruct = {0};

  LL_RCC_SetUSARTClockSource(LL_RCC_USART2_CLKSOURCE_PCLK1);

  /* Peripheral clock enable */
  LL_APB1_GRP1_EnableClock(LL_APB1_GRP1_PERIPH_USART2);

  LL_AHB2_GRP1_EnableClock(LL_AHB2_GRP1_PERIPH_GPIOA);
  /**USART2 GPIO Configuration
  PA1   ------> USART2_DE
  PA2   ------> USART2_TX
  PA3   ------> USART2_RX
  */
  GPIO_InitStruct.Pin = LL_GPIO_PIN_1|LL_GPIO_PIN_2|LL_GPIO_PIN_3;
  GPIO_InitStruct.Mode = LL_GPIO_MODE_ALTERNATE;
  GPIO_InitStruct.Speed = LL_GPIO_SPEED_FREQ_HIGH;
  GPIO_InitStruct.OutputType = LL_GPIO_OUTPUT_PUSHPULL;
  GPIO_InitStruct.Pull = LL_GPIO_PULL_NO;
  GPIO_InitStruct.Alternate = LL_GPIO_AF_7;
  LL_GPIO_Init(GPIOA, &GPIO_InitStruct);

  /* USART2 DMA Init */

  /* GPDMA1_REQUEST_USART2_RX Init */
  NodeConfig.DestAllocatedPort = LL_DMA_DEST_ALLOCATED_PORT1;
  NodeConfig.DestHWordExchange = LL_DMA_DEST_HALFWORD_PRESERVE;
  NodeConfig.DestByteExchange = LL_DMA_DEST_BYTE_PRESERVE;
  NodeConfig.DestBurstLength = 1;
  NodeConfig.DestIncMode = LL_DMA_DEST_INCREMENT;
  NodeConfig.DestDataWidth = LL_DMA_DEST_DATAWIDTH_BYTE;
  NodeConfig.SrcAllocatedPort = LL_DMA_SRC_ALLOCATED_PORT0;
  NodeConfig.SrcByteExchange = LL_DMA_SRC_BYTE_PRESERVE;
  NodeConfig.DataAlignment = LL_DMA_DATA_ALIGN_ZEROPADD;
  NodeConfig.SrcBurstLength = 1;
  NodeConfig.SrcIncMode = LL_DMA_SRC_FIXED;
  NodeConfig.SrcDataWidth = LL_DMA_SRC_DATAWIDTH_BYTE;
  NodeConfig.TransferEventMode = LL_DMA_TCEM_BLK_TRANSFER;
  NodeConfig.Mode = LL_DMA_NORMAL;
  NodeConfig.TriggerPolarity = LL_DMA_TRIG_POLARITY_MASKED;
  NodeConfig.BlkHWRequest = LL_DMA_HWREQUEST_SINGLEBURST;
  NodeConfig.Direction = LL_DMA_DIRECTION_PERIPH_TO_MEMORY;
  NodeConfig.Request = LL_GPDMA1_REQUEST_USART2_RX;
  NodeConfig.UpdateRegisters = (LL_DMA_UPDATE_CTR1 | LL_DMA_UPDATE_CTR2 | LL_DMA_UPDATE_CBR1 | LL_DMA_UPDATE_CSAR | LL_DMA_UPDATE_CDAR | LL_DMA_UPDATE_CTR3 | LL_DMA_UPDATE_CBR2 | LL_DMA_UPDATE_CLLR);
  NodeConfig.NodeType = LL_DMA_GPDMA_LINEAR_NODE;
  LL_DMA_CreateLinkNode(&NodeConfig, &Node_GPDMA1_Channel3);

  LL_DMA_ConnectLinkNode(&Node_GPDMA1_Channel3, LL_DMA_CLLR_OFFSET5, &Node_GPDMA1_Channel3, LL_DMA_CLLR_OFFSET5);

  /* Next function call is commented because it will not compile as is. The Node structure address has to be cast to an unsigned int (uint32_t)pNode_DMAxCHy */
  /*

  */
  LL_DMA_SetLinkedListBaseAddr(GPDMA1, LL_DMA_CHANNEL_3, (uint32_t)&Node_GPDMA1_Channel3);

  DMA_InitLinkedListStruct.Priority = LL_DMA_LOW_PRIORITY_LOW_WEIGHT;
  DMA_InitLinkedListStruct.LinkStepMode = LL_DMA_LSM_FULL_EXECUTION;
  DMA_InitLinkedListStruct.LinkAllocatedPort = LL_DMA_LINK_ALLOCATED_PORT1;
  DMA_InitLinkedListStruct.TransferEventMode = LL_DMA_TCEM_BLK_TRANSFER;
  LL_DMA_List_Init(GPDMA1, LL_DMA_CHANNEL_3, &DMA_InitLinkedListStruct);

  /* GPDMA1_REQUEST_USART2_TX Init */
  DMA_InitStruct.SrcAddress = 0x00000000U;
  DMA_InitStruct.DestAddress = 0x00000000U;
  DMA_InitStruct.Direction = LL_DMA_DIRECTION_MEMORY_TO_PERIPH;
  DMA_InitStruct.BlkHWRequest = LL_DMA_HWREQUEST_SINGLEBURST;
  DMA_InitStruct.DataAlignment = LL_DMA_DATA_ALIGN_ZEROPADD;
  DMA_InitStruct.SrcBurstLength = 1;
  DMA_InitStruct.DestBurstLength = 1;
  DMA_InitStruct.SrcDataWidth = LL_DMA_SRC_DATAWIDTH_BYTE;
  DMA_InitStruct.DestDataWidth = LL_DMA_DEST_DATAWIDTH_BYTE;
  DMA_InitStruct.SrcIncMode = LL_DMA_SRC_INCREMENT;
  DMA_InitStruct.DestIncMode = LL_DMA_DEST_FIXED;
  DMA_InitStruct.Priority = LL_DMA_LOW_PRIORITY_LOW_WEIGHT;
  DMA_InitStruct.BlkDataLength = 0x00000000U;
  DMA_InitStruct.TriggerMode = LL_DMA_TRIGM_BLK_TRANSFER;
  DMA_InitStruct.TriggerPolarity = LL_DMA_TRIG_POLARITY_MASKED;
  DMA_InitStruct.TriggerSelection = 0x00000000U;
  DMA_InitStruct.Request = LL_GPDMA1_REQUEST_USART2_TX;
  DMA_InitStruct.TransferEventMode = LL_DMA_TCEM_BLK_TRANSFER;
  DMA_InitStruct.Mode = LL_DMA_NORMAL;
  DMA_InitStruct.SrcAllocatedPort = LL_DMA_SRC_ALLOCATED_PORT1;
  DMA_InitStruct.DestAllocatedPort = LL_DMA_DEST_ALLOCATED_PORT0;
  DMA_InitStruct.LinkAllocatedPort = LL_DMA_LINK_ALLOCATED_PORT1;
  DMA_InitStruct.LinkStepMode = LL_DMA_LSM_FULL_EXECUTION;
  DMA_InitStruct.LinkedListBaseAddr = 0x00000000U;
  DMA_InitStruct.LinkedListAddrOffset = 0x00000000U;
  LL_DMA_Init(GPDMA1, LL_DMA_CHANNEL_2, &DMA_InitStruct);

  /* USER CODE BEGIN USART2_Init 1 */

  LL_DMA_ConfigLinkUpdate(GPDMA1, LL_DMA_CHANNEL_3, LL_DMA_UPDATE_CTR1 | LL_DMA_UPDATE_CTR2 |LL_DMA_UPDATE_CBR1 | LL_DMA_UPDATE_CSAR | LL_DMA_UPDATE_CDAR | LL_DMA_UPDATE_CLLR, (uint32_t)&Node_GPDMA1_Channel3);
  LL_DMA_EnableChannel(GPDMA1, LL_DMA_CHANNEL_3);
  LL_DMA_SetLinkedListAddrOffset(GPDMA1, LL_DMA_CHANNEL_3, LL_DMA_CLLR_OFFSET5);
  LL_USART_EnableDMAReq_RX(USART2);

  LL_DMA_SetDestAddress(GPDMA1, LL_DMA_CHANNEL_2, LL_USART_DMA_GetRegAddr(USART2, LL_USART_DMA_REG_DATA_TRANSMIT));
  LL_USART_EnableDMAReq_TX(USART2);

  /* USER CODE END USART2_Init 1 */
  USART_InitStruct.PrescalerValue = LL_USART_PRESCALER_DIV1;
  USART_InitStruct.BaudRate = 5000000;
  USART_InitStruct.DataWidth = LL_USART_DATAWIDTH_8B;
  USART_InitStruct.StopBits = LL_USART_STOPBITS_1;
  USART_InitStruct.Parity = LL_USART_PARITY_NONE;
  USART_InitStruct.TransferDirection = LL_USART_DIRECTION_TX_RX;
  USART_InitStruct.HardwareFlowControl = LL_USART_HWCONTROL_NONE;
  USART_InitStruct.OverSampling = LL_USART_OVERSAMPLING_16;
  LL_USART_Init(USART2, &USART_InitStruct);
  LL_USART_SetTXFIFOThreshold(USART2, LL_USART_FIFOTHRESHOLD_1_8);
  LL_USART_SetRXFIFOThreshold(USART2, LL_USART_FIFOTHRESHOLD_1_8);
  LL_USART_EnableDEMode(USART2);
  LL_USART_SetDESignalPolarity(USART2, LL_USART_DE_POLARITY_HIGH);
  LL_USART_SetDEAssertionTime(USART2, 0);
  LL_USART_SetDEDeassertionTime(USART2, 0);
  LL_USART_DisableFIFO(USART2);
  LL_USART_ConfigAsyncMode(USART2);
  LL_USART_Enable(USART2);

}

static void MX_USART3_UART_Init(void)
{

  /* USER CODE BEGIN USART3_Init 0 */

  // WARNING
  // Remove the second redefinition of NodeConfig after Cube MX code generation.
  LL_DMA_InitNodeTypeDef NodeConfig = {0};

  NodeConfig.SrcAddress        = (uint32_t)LL_USART_DMA_GetRegAddr(USART3, LL_USART_DMA_REG_DATA_RECEIVE);
  NodeConfig.DestAddress       = (uint32_t)&Usart3RxDmaBuf;
  NodeConfig.BlkDataLength     = ARRAY_COUNT(Usart3RxDmaBuf);

  /* USER CODE END USART3_Init 0 */

  LL_USART_InitTypeDef USART_InitStruct = {0};

  LL_GPIO_InitTypeDef GPIO_InitStruct = {0};
  LL_DMA_InitLinkedListTypeDef DMA_InitLinkedListStruct = {0};
  LL_DMA_InitTypeDef DMA_InitStruct = {0};

  LL_RCC_SetUSARTClockSource(LL_RCC_USART3_CLKSOURCE_PCLK1);

  /* Peripheral clock enable */
  LL_APB1_GRP1_EnableClock(LL_APB1_GRP1_PERIPH_USART3);

  LL_AHB2_GRP1_EnableClock(LL_AHB2_GRP1_PERIPH_GPIOB);
  /**USART3 GPIO Configuration
  PB1   ------> USART3_RX
  PB10   ------> USART3_TX
  PB14   ------> USART3_DE
  */
  GPIO_InitStruct.Pin = LL_GPIO_PIN_1|LL_GPIO_PIN_10|LL_GPIO_PIN_14;
  GPIO_InitStruct.Mode = LL_GPIO_MODE_ALTERNATE;
  GPIO_InitStruct.Speed = LL_GPIO_SPEED_FREQ_HIGH;
  GPIO_InitStruct.OutputType = LL_GPIO_OUTPUT_PUSHPULL;
  GPIO_InitStruct.Pull = LL_GPIO_PULL_NO;
  GPIO_InitStruct.Alternate = LL_GPIO_AF_7;
  LL_GPIO_Init(GPIOB, &GPIO_InitStruct);

  /* USART3 DMA Init */

  /* GPDMA1_REQUEST_USART3_RX Init */
  NodeConfig.DestAllocatedPort = LL_DMA_DEST_ALLOCATED_PORT1;
  NodeConfig.DestHWordExchange = LL_DMA_DEST_HALFWORD_PRESERVE;
  NodeConfig.DestByteExchange = LL_DMA_DEST_BYTE_PRESERVE;
  NodeConfig.DestBurstLength = 1;
  NodeConfig.DestIncMode = LL_DMA_DEST_INCREMENT;
  NodeConfig.DestDataWidth = LL_DMA_DEST_DATAWIDTH_BYTE;
  NodeConfig.SrcAllocatedPort = LL_DMA_SRC_ALLOCATED_PORT0;
  NodeConfig.SrcByteExchange = LL_DMA_SRC_BYTE_PRESERVE;
  NodeConfig.DataAlignment = LL_DMA_DATA_ALIGN_ZEROPADD;
  NodeConfig.SrcBurstLength = 1;
  NodeConfig.SrcIncMode = LL_DMA_SRC_FIXED;
  NodeConfig.SrcDataWidth = LL_DMA_SRC_DATAWIDTH_BYTE;
  NodeConfig.TransferEventMode = LL_DMA_TCEM_BLK_TRANSFER;
  NodeConfig.Mode = LL_DMA_NORMAL;
  NodeConfig.TriggerPolarity = LL_DMA_TRIG_POLARITY_MASKED;
  NodeConfig.BlkHWRequest = LL_DMA_HWREQUEST_SINGLEBURST;
  NodeConfig.Direction = LL_DMA_DIRECTION_PERIPH_TO_MEMORY;
  NodeConfig.Request = LL_GPDMA1_REQUEST_USART3_RX;
  NodeConfig.UpdateRegisters = (LL_DMA_UPDATE_CTR1 | LL_DMA_UPDATE_CTR2 | LL_DMA_UPDATE_CBR1 | LL_DMA_UPDATE_CSAR | LL_DMA_UPDATE_CDAR | LL_DMA_UPDATE_CTR3 | LL_DMA_UPDATE_CBR2 | LL_DMA_UPDATE_CLLR);
  NodeConfig.NodeType = LL_DMA_GPDMA_LINEAR_NODE;
  LL_DMA_CreateLinkNode(&NodeConfig, &Node_GPDMA1_Channel1);

  LL_DMA_ConnectLinkNode(&Node_GPDMA1_Channel1, LL_DMA_CLLR_OFFSET5, &Node_GPDMA1_Channel1, LL_DMA_CLLR_OFFSET5);

  /* Next function call is commented because it will not compile as is. The Node structure address has to be cast to an unsigned int (uint32_t)pNode_DMAxCHy */
  /*

  */
  LL_DMA_SetLinkedListBaseAddr(GPDMA1, LL_DMA_CHANNEL_1, (uint32_t)&Node_GPDMA1_Channel1);

  DMA_InitLinkedListStruct.Priority = LL_DMA_LOW_PRIORITY_LOW_WEIGHT;
  DMA_InitLinkedListStruct.LinkStepMode = LL_DMA_LSM_FULL_EXECUTION;
  DMA_InitLinkedListStruct.LinkAllocatedPort = LL_DMA_LINK_ALLOCATED_PORT1;
  DMA_InitLinkedListStruct.TransferEventMode = LL_DMA_TCEM_BLK_TRANSFER;
  LL_DMA_List_Init(GPDMA1, LL_DMA_CHANNEL_1, &DMA_InitLinkedListStruct);

  /* GPDMA1_REQUEST_USART3_TX Init */
  DMA_InitStruct.SrcAddress = 0x00000000U;
  DMA_InitStruct.DestAddress = 0x00000000U;
  DMA_InitStruct.Direction = LL_DMA_DIRECTION_MEMORY_TO_PERIPH;
  DMA_InitStruct.BlkHWRequest = LL_DMA_HWREQUEST_SINGLEBURST;
  DMA_InitStruct.DataAlignment = LL_DMA_DATA_ALIGN_ZEROPADD;
  DMA_InitStruct.SrcBurstLength = 1;
  DMA_InitStruct.DestBurstLength = 1;
  DMA_InitStruct.SrcDataWidth = LL_DMA_SRC_DATAWIDTH_BYTE;
  DMA_InitStruct.DestDataWidth = LL_DMA_DEST_DATAWIDTH_BYTE;
  DMA_InitStruct.SrcIncMode = LL_DMA_SRC_INCREMENT;
  DMA_InitStruct.DestIncMode = LL_DMA_DEST_FIXED;
  DMA_InitStruct.Priority = LL_DMA_LOW_PRIORITY_LOW_WEIGHT;
  DMA_InitStruct.BlkDataLength = 0x00000000U;
  DMA_InitStruct.TriggerMode = LL_DMA_TRIGM_BLK_TRANSFER;
  DMA_InitStruct.TriggerPolarity = LL_DMA_TRIG_POLARITY_MASKED;
  DMA_InitStruct.TriggerSelection = 0x00000000U;
  DMA_InitStruct.Request = LL_GPDMA1_REQUEST_USART3_TX;
  DMA_InitStruct.TransferEventMode = LL_DMA_TCEM_BLK_TRANSFER;
  DMA_InitStruct.Mode = LL_DMA_NORMAL;
  DMA_InitStruct.SrcAllocatedPort = LL_DMA_SRC_ALLOCATED_PORT1;
  DMA_InitStruct.DestAllocatedPort = LL_DMA_DEST_ALLOCATED_PORT0;
  DMA_InitStruct.LinkAllocatedPort = LL_DMA_LINK_ALLOCATED_PORT1;
  DMA_InitStruct.LinkStepMode = LL_DMA_LSM_FULL_EXECUTION;
  DMA_InitStruct.LinkedListBaseAddr = 0x00000000U;
  DMA_InitStruct.LinkedListAddrOffset = 0x00000000U;
  LL_DMA_Init(GPDMA1, LL_DMA_CHANNEL_0, &DMA_InitStruct);

  /* USER CODE BEGIN USART3_Init 1 */

  LL_DMA_ConfigLinkUpdate(GPDMA1, LL_DMA_CHANNEL_1, LL_DMA_UPDATE_CTR1 | LL_DMA_UPDATE_CTR2 |LL_DMA_UPDATE_CBR1 | LL_DMA_UPDATE_CSAR | LL_DMA_UPDATE_CDAR | LL_DMA_UPDATE_CLLR, (uint32_t)&Node_GPDMA1_Channel1);
  LL_DMA_EnableChannel(GPDMA1, LL_DMA_CHANNEL_1);
  LL_DMA_SetLinkedListAddrOffset(GPDMA1, LL_DMA_CHANNEL_1, LL_DMA_CLLR_OFFSET5);
  LL_USART_EnableDMAReq_RX(USART3);

  LL_DMA_SetDestAddress(GPDMA1, LL_DMA_CHANNEL_0, LL_USART_DMA_GetRegAddr(USART3, LL_USART_DMA_REG_DATA_TRANSMIT));
  LL_USART_EnableDMAReq_TX(USART3);

  /* USER CODE END USART3_Init 1 */
  USART_InitStruct.PrescalerValue = LL_USART_PRESCALER_DIV1;
  USART_InitStruct.BaudRate = 5000000;
  USART_InitStruct.DataWidth = LL_USART_DATAWIDTH_8B;
  USART_InitStruct.StopBits = LL_USART_STOPBITS_1;
  USART_InitStruct.Parity = LL_USART_PARITY_NONE;
  USART_InitStruct.TransferDirection = LL_USART_DIRECTION_TX_RX;
  USART_InitStruct.HardwareFlowControl = LL_USART_HWCONTROL_NONE;
  USART_InitStruct.OverSampling = LL_USART_OVERSAMPLING_16;
  LL_USART_Init(USART3, &USART_InitStruct);
  LL_USART_SetTXFIFOThreshold(USART3, LL_USART_FIFOTHRESHOLD_1_8);
  LL_USART_SetRXFIFOThreshold(USART3, LL_USART_FIFOTHRESHOLD_1_8);
  LL_USART_EnableDEMode(USART3);
  LL_USART_SetDESignalPolarity(USART3, LL_USART_DE_POLARITY_HIGH);
  LL_USART_SetDEAssertionTime(USART3, 0);
  LL_USART_SetDEDeassertionTime(USART3, 0);
  LL_USART_DisableFIFO(USART3);
  LL_USART_ConfigAsyncMode(USART3);
  LL_USART_Enable(USART3);

}

static void MX_GPIO_Init(void)
{
  LL_GPIO_InitTypeDef GPIO_InitStruct = {0};

  /* GPIO Ports Clock Enable */
  LL_AHB2_GRP1_EnableClock(LL_AHB2_GRP1_PERIPH_GPIOC);
  LL_AHB2_GRP1_EnableClock(LL_AHB2_GRP1_PERIPH_GPIOH);
  LL_AHB2_GRP1_EnableClock(LL_AHB2_GRP1_PERIPH_GPIOA);
  LL_AHB2_GRP1_EnableClock(LL_AHB2_GRP1_PERIPH_GPIOB);
  LL_AHB2_GRP1_EnableClock(LL_AHB2_GRP1_PERIPH_GPIOD);

  /**/
  LL_GPIO_ResetOutputPin(GPIOC, SHR_CLK_Pin|SHR_STR_Pin|LCDA_CS_Pin|LCDB_CS_Pin);

  /**/
  LL_GPIO_ResetOutputPin(GPIOB, LCD_RST_Pin|LCD_DC_Pin|SHR_DOUT_DISP_Pin);

  /**/
  LL_GPIO_SetOutputPin(GPIOA, CODEC_RST_Pin|SHR_DIN_KBD_LED_B_Pin);

  /**/
  GPIO_InitStruct.Pin = KBDA_RIGHT_UP_Pin|KBDA_LEFT_UP_Pin|KBDA_RIGHT_DOWN_Pin|KBDB_LEFT_UP_Pin
                          |KBDB_RIGHT_UP_Pin;
  GPIO_InitStruct.Mode = LL_GPIO_MODE_INPUT;
  GPIO_InitStruct.Pull = LL_GPIO_PULL_UP;
  LL_GPIO_Init(GPIOC, &GPIO_InitStruct);

  /**/
  GPIO_InitStruct.Pin = SHR_CLK_Pin|SHR_STR_Pin;
  GPIO_InitStruct.Mode = LL_GPIO_MODE_OUTPUT;
  GPIO_InitStruct.Speed = LL_GPIO_SPEED_FREQ_LOW;
  GPIO_InitStruct.OutputType = LL_GPIO_OUTPUT_PUSHPULL;
  GPIO_InitStruct.Pull = LL_GPIO_PULL_NO;
  LL_GPIO_Init(GPIOC, &GPIO_InitStruct);

  /**/
  GPIO_InitStruct.Pin = CODEC_RST_Pin;
  GPIO_InitStruct.Mode = LL_GPIO_MODE_OUTPUT;
  GPIO_InitStruct.Speed = LL_GPIO_SPEED_FREQ_LOW;
  GPIO_InitStruct.OutputType = LL_GPIO_OUTPUT_OPENDRAIN;
  GPIO_InitStruct.Pull = LL_GPIO_PULL_UP;
  LL_GPIO_Init(CODEC_RST_GPIO_Port, &GPIO_InitStruct);

  /**/
  GPIO_InitStruct.Pin = LCDA_CS_Pin|LCDB_CS_Pin;
  GPIO_InitStruct.Mode = LL_GPIO_MODE_OUTPUT;
  GPIO_InitStruct.Speed = LL_GPIO_SPEED_FREQ_MEDIUM;
  GPIO_InitStruct.OutputType = LL_GPIO_OUTPUT_PUSHPULL;
  GPIO_InitStruct.Pull = LL_GPIO_PULL_NO;
  LL_GPIO_Init(GPIOC, &GPIO_InitStruct);

  /**/
  GPIO_InitStruct.Pin = LCD_RST_Pin|LCD_DC_Pin|SHR_DOUT_DISP_Pin;
  GPIO_InitStruct.Mode = LL_GPIO_MODE_OUTPUT;
  GPIO_InitStruct.Speed = LL_GPIO_SPEED_FREQ_LOW;
  GPIO_InitStruct.OutputType = LL_GPIO_OUTPUT_PUSHPULL;
  GPIO_InitStruct.Pull = LL_GPIO_PULL_NO;
  LL_GPIO_Init(GPIOB, &GPIO_InitStruct);

  /**/
  GPIO_InitStruct.Pin = SHR_DIN_KBD_LED_B_Pin;
  GPIO_InitStruct.Mode = LL_GPIO_MODE_OUTPUT;
  GPIO_InitStruct.Speed = LL_GPIO_SPEED_FREQ_LOW;
  GPIO_InitStruct.OutputType = LL_GPIO_OUTPUT_PUSHPULL;
  GPIO_InitStruct.Pull = LL_GPIO_PULL_NO;
  LL_GPIO_Init(SHR_DIN_KBD_LED_B_GPIO_Port, &GPIO_InitStruct);

  /**/
  GPIO_InitStruct.Pin = KBDB_LEFT_DOWN_Pin;
  GPIO_InitStruct.Mode = LL_GPIO_MODE_INPUT;
  GPIO_InitStruct.Pull = LL_GPIO_PULL_UP;
  LL_GPIO_Init(KBDB_LEFT_DOWN_GPIO_Port, &GPIO_InitStruct);

}

void Error_Handler(void)
{
  __disable_irq();
  while (1)
  {
  }
}
